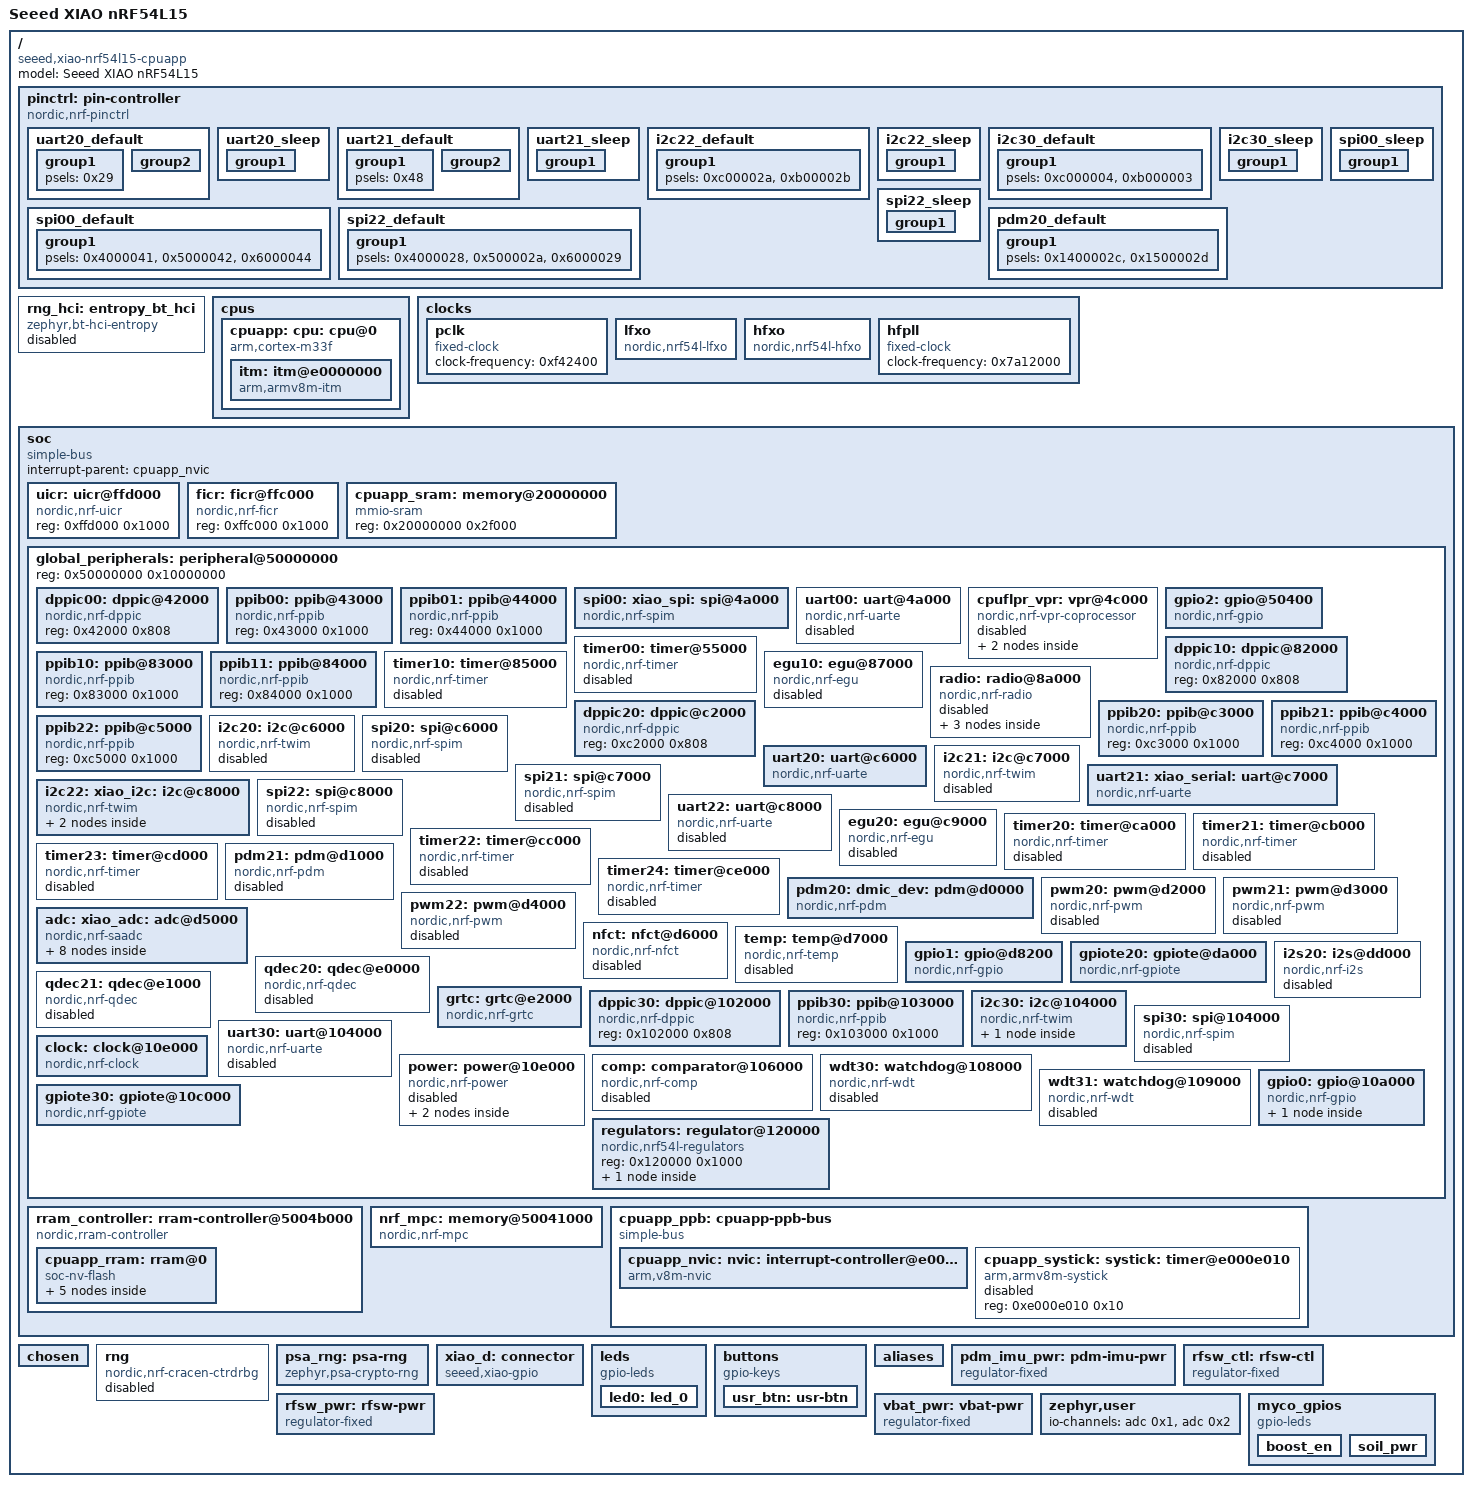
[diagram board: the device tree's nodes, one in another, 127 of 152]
/dts-v1/;

/* node '/' defined in zephyr/dts/vendor/nordic/nrf_common.dtsi:25 */
/ {
	#address-cells = < 0x1 >;                  /* in zephyr/dts/vendor/nordic/nrf54l_05_10_15.dtsi:19 */
	#size-cells = < 0x1 >;                     /* in zephyr/dts/vendor/nordic/nrf54l_05_10_15.dtsi:20 */
	model = "Seeed XIAO nRF54L15";             /* in zephyr/boards/seeed/xiao_nrf54l15/xiao_nrf54l15_nrf54l15_cpuapp.dts:11 */
	compatible = "seeed,xiao-nrf54l15-cpuapp"; /* in zephyr/boards/seeed/xiao_nrf54l15/xiao_nrf54l15_nrf54l15_cpuapp.dts:12 */

	/* node '/pin-controller' defined in zephyr/dts/vendor/nordic/nrf_common.dtsi:26 */
	pinctrl: pin-controller {
		compatible = "nordic,nrf-pinctrl"; /* in zephyr/dts/vendor/nordic/nrf_common.dtsi:31 */

		/* node '/pin-controller/uart20_default' defined in zephyr/boards/seeed/xiao_nrf54l15/xiao_nrf54l15-pinctrl.dtsi:6 */
		uart20_default: uart20_default {
			phandle = < 0x6 >; /* in zephyr/boards/seeed/xiao_nrf54l15/xiao_nrf54l15_common.dtsi:39 */

			/* node '/pin-controller/uart20_default/group1' defined in zephyr/boards/seeed/xiao_nrf54l15/xiao_nrf54l15-pinctrl.dtsi:7 */
			group1 {
				psels = < 0x29 >; /* in zephyr/boards/seeed/xiao_nrf54l15/xiao_nrf54l15-pinctrl.dtsi:8 */
			};

			/* node '/pin-controller/uart20_default/group2' defined in zephyr/boards/seeed/xiao_nrf54l15/xiao_nrf54l15-pinctrl.dtsi:11 */
			group2 {
				psels = < 0x1000028 >; /* in zephyr/boards/seeed/xiao_nrf54l15/xiao_nrf54l15-pinctrl.dtsi:12 */
				bias-pull-up;          /* in zephyr/boards/seeed/xiao_nrf54l15/xiao_nrf54l15-pinctrl.dtsi:13 */
			};
		};

		/* node '/pin-controller/uart20_sleep' defined in zephyr/boards/seeed/xiao_nrf54l15/xiao_nrf54l15-pinctrl.dtsi:17 */
		uart20_sleep: uart20_sleep {
			phandle = < 0x7 >; /* in zephyr/boards/seeed/xiao_nrf54l15/xiao_nrf54l15_common.dtsi:40 */

			/* node '/pin-controller/uart20_sleep/group1' defined in zephyr/boards/seeed/xiao_nrf54l15/xiao_nrf54l15-pinctrl.dtsi:18 */
			group1 {
				psels = < 0x29 >,
				        < 0x1000028 >; /* in zephyr/boards/seeed/xiao_nrf54l15/xiao_nrf54l15-pinctrl.dtsi:19 */
				low-power-enable;      /* in zephyr/boards/seeed/xiao_nrf54l15/xiao_nrf54l15-pinctrl.dtsi:21 */
			};
		};

		/* node '/pin-controller/uart21_default' defined in zephyr/boards/seeed/xiao_nrf54l15/xiao_nrf54l15-pinctrl.dtsi:25 */
		uart21_default: uart21_default {
			phandle = < 0x8 >; /* in zephyr/boards/seeed/xiao_nrf54l15/xiao_nrf54l15_common.dtsi:46 */

			/* node '/pin-controller/uart21_default/group1' defined in zephyr/boards/seeed/xiao_nrf54l15/xiao_nrf54l15-pinctrl.dtsi:26 */
			group1 {
				psels = < 0x48 >; /* in zephyr/boards/seeed/xiao_nrf54l15/xiao_nrf54l15-pinctrl.dtsi:27 */
			};

			/* node '/pin-controller/uart21_default/group2' defined in zephyr/boards/seeed/xiao_nrf54l15/xiao_nrf54l15-pinctrl.dtsi:30 */
			group2 {
				psels = < 0x1000047 >; /* in zephyr/boards/seeed/xiao_nrf54l15/xiao_nrf54l15-pinctrl.dtsi:31 */
				bias-pull-up;          /* in zephyr/boards/seeed/xiao_nrf54l15/xiao_nrf54l15-pinctrl.dtsi:32 */
			};
		};

		/* node '/pin-controller/uart21_sleep' defined in zephyr/boards/seeed/xiao_nrf54l15/xiao_nrf54l15-pinctrl.dtsi:36 */
		uart21_sleep: uart21_sleep {
			phandle = < 0x9 >; /* in zephyr/boards/seeed/xiao_nrf54l15/xiao_nrf54l15_common.dtsi:47 */

			/* node '/pin-controller/uart21_sleep/group1' defined in zephyr/boards/seeed/xiao_nrf54l15/xiao_nrf54l15-pinctrl.dtsi:37 */
			group1 {
				psels = < 0x48 >,
				        < 0x1000047 >; /* in zephyr/boards/seeed/xiao_nrf54l15/xiao_nrf54l15-pinctrl.dtsi:38 */
				low-power-enable;      /* in zephyr/boards/seeed/xiao_nrf54l15/xiao_nrf54l15-pinctrl.dtsi:40 */
			};
		};

		/* node '/pin-controller/i2c22_default' defined in zephyr/boards/seeed/xiao_nrf54l15/xiao_nrf54l15-pinctrl.dtsi:44 */
		i2c22_default: i2c22_default {
			phandle = < 0xa >; /* in zephyr/boards/seeed/xiao_nrf54l15/xiao_nrf54l15_common.dtsi:52 */

			/* node '/pin-controller/i2c22_default/group1' defined in zephyr/boards/seeed/xiao_nrf54l15/xiao_nrf54l15-pinctrl.dtsi:45 */
			group1 {
				psels = < 0xc00002a >,
				        < 0xb00002b >; /* in zephyr/boards/seeed/xiao_nrf54l15/xiao_nrf54l15-pinctrl.dtsi:46 */
			};
		};

		/* node '/pin-controller/i2c22_sleep' defined in zephyr/boards/seeed/xiao_nrf54l15/xiao_nrf54l15-pinctrl.dtsi:51 */
		i2c22_sleep: i2c22_sleep {
			phandle = < 0xb >; /* in zephyr/boards/seeed/xiao_nrf54l15/xiao_nrf54l15_common.dtsi:53 */

			/* node '/pin-controller/i2c22_sleep/group1' defined in zephyr/boards/seeed/xiao_nrf54l15/xiao_nrf54l15-pinctrl.dtsi:52 */
			group1 {
				psels = < 0xc00002a >,
				        < 0xb00002b >; /* in zephyr/boards/seeed/xiao_nrf54l15/xiao_nrf54l15-pinctrl.dtsi:53 */
				low-power-enable;      /* in zephyr/boards/seeed/xiao_nrf54l15/xiao_nrf54l15-pinctrl.dtsi:55 */
			};
		};

		/* node '/pin-controller/i2c30_default' defined in zephyr/boards/seeed/xiao_nrf54l15/xiao_nrf54l15-pinctrl.dtsi:59 */
		i2c30_default: i2c30_default {
			phandle = < 0x12 >; /* in zephyr/boards/seeed/xiao_nrf54l15/xiao_nrf54l15_common.dtsi:59 */

			/* node '/pin-controller/i2c30_default/group1' defined in zephyr/boards/seeed/xiao_nrf54l15/xiao_nrf54l15-pinctrl.dtsi:60 */
			group1 {
				psels = < 0xc000004 >,
				        < 0xb000003 >; /* in zephyr/boards/seeed/xiao_nrf54l15/xiao_nrf54l15-pinctrl.dtsi:61 */
			};
		};

		/* node '/pin-controller/i2c30_sleep' defined in zephyr/boards/seeed/xiao_nrf54l15/xiao_nrf54l15-pinctrl.dtsi:66 */
		i2c30_sleep: i2c30_sleep {
			phandle = < 0x13 >; /* in zephyr/boards/seeed/xiao_nrf54l15/xiao_nrf54l15_common.dtsi:60 */

			/* node '/pin-controller/i2c30_sleep/group1' defined in zephyr/boards/seeed/xiao_nrf54l15/xiao_nrf54l15-pinctrl.dtsi:67 */
			group1 {
				psels = < 0xc000004 >,
				        < 0xb000003 >; /* in zephyr/boards/seeed/xiao_nrf54l15/xiao_nrf54l15-pinctrl.dtsi:68 */
				low-power-enable;      /* in zephyr/boards/seeed/xiao_nrf54l15/xiao_nrf54l15-pinctrl.dtsi:70 */
			};
		};

		/* node '/pin-controller/spi00_default' defined in zephyr/boards/seeed/xiao_nrf54l15/xiao_nrf54l15-pinctrl.dtsi:74 */
		spi00_default: spi00_default {
			phandle = < 0x3 >; /* in zephyr/boards/seeed/xiao_nrf54l15/xiao_nrf54l15_common.dtsi:66 */

			/* node '/pin-controller/spi00_default/group1' defined in zephyr/boards/seeed/xiao_nrf54l15/xiao_nrf54l15-pinctrl.dtsi:75 */
			group1 {
				psels = < 0x4000041 >,
				        < 0x5000042 >,
				        < 0x6000044 >; /* in zephyr/boards/seeed/xiao_nrf54l15/xiao_nrf54l15-pinctrl.dtsi:76 */
			};
		};

		/* node '/pin-controller/spi00_sleep' defined in zephyr/boards/seeed/xiao_nrf54l15/xiao_nrf54l15-pinctrl.dtsi:82 */
		spi00_sleep: spi00_sleep {
			phandle = < 0x4 >; /* in zephyr/boards/seeed/xiao_nrf54l15/xiao_nrf54l15_common.dtsi:67 */

			/* node '/pin-controller/spi00_sleep/group1' defined in zephyr/boards/seeed/xiao_nrf54l15/xiao_nrf54l15-pinctrl.dtsi:83 */
			group1 {
				psels = < 0x4000041 >,
				        < 0x5000042 >,
				        < 0x6000044 >; /* in zephyr/boards/seeed/xiao_nrf54l15/xiao_nrf54l15-pinctrl.dtsi:84 */
				low-power-enable;      /* in zephyr/boards/seeed/xiao_nrf54l15/xiao_nrf54l15-pinctrl.dtsi:87 */
			};
		};

		/* node '/pin-controller/spi22_default' defined in zephyr/boards/seeed/xiao_nrf54l15/xiao_nrf54l15-pinctrl.dtsi:91 */
		spi22_default: spi22_default {
			phandle = < 0xc >; /* in zephyr/boards/seeed/xiao_nrf54l15/xiao_nrf54l15_common.dtsi:72 */

			/* node '/pin-controller/spi22_default/group1' defined in zephyr/boards/seeed/xiao_nrf54l15/xiao_nrf54l15-pinctrl.dtsi:92 */
			group1 {
				psels = < 0x4000028 >,
				        < 0x500002a >,
				        < 0x6000029 >; /* in zephyr/boards/seeed/xiao_nrf54l15/xiao_nrf54l15-pinctrl.dtsi:93 */
			};
		};

		/* node '/pin-controller/spi22_sleep' defined in zephyr/boards/seeed/xiao_nrf54l15/xiao_nrf54l15-pinctrl.dtsi:99 */
		spi22_sleep: spi22_sleep {
			phandle = < 0xd >; /* in zephyr/boards/seeed/xiao_nrf54l15/xiao_nrf54l15_common.dtsi:73 */

			/* node '/pin-controller/spi22_sleep/group1' defined in zephyr/boards/seeed/xiao_nrf54l15/xiao_nrf54l15-pinctrl.dtsi:100 */
			group1 {
				psels = < 0x4000028 >,
				        < 0x500002a >,
				        < 0x6000029 >; /* in zephyr/boards/seeed/xiao_nrf54l15/xiao_nrf54l15-pinctrl.dtsi:101 */
				low-power-enable;      /* in zephyr/boards/seeed/xiao_nrf54l15/xiao_nrf54l15-pinctrl.dtsi:104 */
			};
		};

		/* node '/pin-controller/pdm20_default' defined in zephyr/boards/seeed/xiao_nrf54l15/xiao_nrf54l15-pinctrl.dtsi:108 */
		pdm20_default: pdm20_default {
			phandle = < 0xe >; /* in zephyr/boards/seeed/xiao_nrf54l15/xiao_nrf54l15_common.dtsi:78 */

			/* node '/pin-controller/pdm20_default/group1' defined in zephyr/boards/seeed/xiao_nrf54l15/xiao_nrf54l15-pinctrl.dtsi:109 */
			group1 {
				psels = < 0x1400002c >,
				        < 0x1500002d >; /* in zephyr/boards/seeed/xiao_nrf54l15/xiao_nrf54l15-pinctrl.dtsi:110 */
			};
		};
	};

	/* node '/entropy_bt_hci' defined in zephyr/dts/vendor/nordic/nrf_common.dtsi:34 */
	rng_hci: entropy_bt_hci {
		compatible = "zephyr,bt-hci-entropy"; /* in zephyr/dts/vendor/nordic/nrf_common.dtsi:35 */
		status = "disabled";                  /* in zephyr/dts/vendor/nordic/nrf_common.dtsi:36 */
	};

	/* node '/cpus' defined in zephyr/dts/vendor/nordic/nrf54l_05_10_15.dtsi:22 */
	cpus {
		#address-cells = < 0x1 >; /* in zephyr/dts/vendor/nordic/nrf54l_05_10_15.dtsi:23 */
		#size-cells = < 0x0 >;    /* in zephyr/dts/vendor/nordic/nrf54l_05_10_15.dtsi:24 */

		/* node '/cpus/cpu@0' defined in zephyr/dts/vendor/nordic/nrf54l_05_10_15.dtsi:26 */
		cpuapp: cpu: cpu@0 {
			compatible = "arm,cortex-m33f"; /* in zephyr/dts/vendor/nordic/nrf54l_05_10_15.dtsi:27 */
			reg = < 0x0 >;                  /* in zephyr/dts/vendor/nordic/nrf54l_05_10_15.dtsi:28 */
			device_type = "cpu";            /* in zephyr/dts/vendor/nordic/nrf54l_05_10_15.dtsi:29 */
			clocks = < &hfpll >;            /* in zephyr/dts/vendor/nordic/nrf54l_05_10_15.dtsi:30 */
			#address-cells = < 0x1 >;       /* in zephyr/dts/vendor/nordic/nrf54l_05_10_15.dtsi:31 */
			#size-cells = < 0x1 >;          /* in zephyr/dts/vendor/nordic/nrf54l_05_10_15.dtsi:32 */

			/* node '/cpus/cpu@0/itm@e0000000' defined in zephyr/dts/vendor/nordic/nrf54l_05_10_15.dtsi:34 */
			itm: itm@e0000000 {
				compatible = "arm,armv8m-itm";     /* in zephyr/dts/vendor/nordic/nrf54l_05_10_15.dtsi:35 */
				reg = < 0xe0000000 0x1000 >;       /* in zephyr/dts/vendor/nordic/nrf54l_05_10_15.dtsi:36 */
				swo-ref-frequency = < 0x7a12000 >; /* in zephyr/dts/vendor/nordic/nrf54l_05_10_15.dtsi:37 */
			};
		};
	};

	/* node '/clocks' defined in zephyr/dts/vendor/nordic/nrf54l_05_10_15.dtsi:51 */
	clocks {

		/* node '/clocks/pclk' defined in zephyr/dts/vendor/nordic/nrf54l_05_10_15.dtsi:52 */
		pclk: pclk {
			compatible = "fixed-clock";     /* in zephyr/dts/vendor/nordic/nrf54l_05_10_15.dtsi:53 */
			#clock-cells = < 0x0 >;         /* in zephyr/dts/vendor/nordic/nrf54l_05_10_15.dtsi:54 */
			clock-frequency = < 0xf42400 >; /* in zephyr/dts/vendor/nordic/nrf54l_05_10_15.dtsi:55 */
			phandle = < 0x11 >;             /* in zephyr/dts/vendor/nordic/nrf54l_05_10_15.dtsi:574 */
		};

		/* node '/clocks/lfxo' defined in zephyr/dts/vendor/nordic/nrf54l_05_10_15.dtsi:58 */
		lfxo: lfxo {
			compatible = "nordic,nrf54l-lfxo";        /* in zephyr/dts/vendor/nordic/nrf54l_05_10_15.dtsi:59 */
			#clock-cells = < 0x0 >;                   /* in zephyr/dts/vendor/nordic/nrf54l_05_10_15.dtsi:60 */
			clock-frequency = < 0x8000 >;             /* in zephyr/dts/vendor/nordic/nrf54l_05_10_15.dtsi:61 */
			load-capacitors = "internal";             /* in zephyr/boards/seeed/xiao_nrf54l15/xiao_nrf54l15_nrf54l15_cpuapp.dts:142 */
			load-capacitance-femtofarad = < 0x3e80 >; /* in zephyr/boards/seeed/xiao_nrf54l15/xiao_nrf54l15_nrf54l15_cpuapp.dts:143 */
			status = "okay";                          /* in zephyr/boards/seeed/xiao_nrf54l15/xiao_nrf54l15_nrf54l15_cpuapp.dts:144 */
			phandle = < 0x10 >;                       /* in zephyr/dts/vendor/nordic/nrf54l_05_10_15.dtsi:574 */
		};

		/* node '/clocks/hfxo' defined in zephyr/dts/vendor/nordic/nrf54l_05_10_15.dtsi:64 */
		hfxo: hfxo {
			compatible = "nordic,nrf54l-hfxo"; /* in zephyr/dts/vendor/nordic/nrf54l_05_10_15.dtsi:65 */
			#clock-cells = < 0x0 >;            /* in zephyr/dts/vendor/nordic/nrf54l_05_10_15.dtsi:66 */
			clock-frequency = < 0x1e84800 >;   /* in zephyr/dts/vendor/nordic/nrf54l_05_10_15.dtsi:67 */
			startup-time-us = < 0x672 >;       /* in zephyr/dts/vendor/nordic/nrf54l_05_10_15.dtsi:68 */
			phandle = < 0x5 >;                 /* in zephyr/dts/vendor/nordic/nrf54l_05_10_15.dtsi:229 */
		};

		/* node '/clocks/hfpll' defined in zephyr/dts/vendor/nordic/nrf54l_05_10_15.dtsi:71 */
		hfpll: hfpll {
			compatible = "fixed-clock";      /* in zephyr/dts/vendor/nordic/nrf54l_05_10_15.dtsi:72 */
			#clock-cells = < 0x0 >;          /* in zephyr/dts/vendor/nordic/nrf54l_05_10_15.dtsi:73 */
			clock-frequency = < 0x7a12000 >; /* in zephyr/dts/vendor/nordic/nrf54l_05_10_15.dtsi:74 */
			phandle = < 0x1 >;               /* in zephyr/dts/vendor/nordic/nrf54l_05_10_15.dtsi:30 */
		};
	};

	/* node '/soc' defined in zephyr/dts/vendor/nordic/nrf54l_05_10_15.dtsi:78 */
	soc {
		#address-cells = < 0x1 >;            /* in zephyr/dts/vendor/nordic/nrf54l_05_10_15.dtsi:79 */
		#size-cells = < 0x1 >;               /* in zephyr/dts/vendor/nordic/nrf54l_05_10_15.dtsi:80 */
		compatible = "simple-bus";           /* in zephyr/dts/arm/nordic/nrf54l_05_10_15_cpuapp.dtsi:25 */
		interrupt-parent = < &cpuapp_nvic >; /* in zephyr/dts/arm/nordic/nrf54l_05_10_15_cpuapp.dtsi:26 */
		ranges;                              /* in zephyr/dts/arm/nordic/nrf54l_05_10_15_cpuapp.dtsi:27 */

		/* node '/soc/uicr@ffd000' defined in zephyr/dts/vendor/nordic/nrf54l_05_10_15.dtsi:85 */
		uicr: uicr@ffd000 {
			compatible = "nordic,nrf-uicr"; /* in zephyr/dts/vendor/nordic/nrf54l_05_10_15.dtsi:86 */
			reg = < 0xffd000 0x1000 >;      /* in zephyr/dts/vendor/nordic/nrf54l_05_10_15.dtsi:87 */
		};

		/* node '/soc/ficr@ffc000' defined in zephyr/dts/vendor/nordic/nrf54l_05_10_15.dtsi:90 */
		ficr: ficr@ffc000 {
			compatible = "nordic,nrf-ficr"; /* in zephyr/dts/vendor/nordic/nrf54l_05_10_15.dtsi:91 */
			reg = < 0xffc000 0x1000 >;      /* in zephyr/dts/vendor/nordic/nrf54l_05_10_15.dtsi:92 */
			#nordic,ficr-cells = < 0x1 >;   /* in zephyr/dts/vendor/nordic/nrf54l_05_10_15.dtsi:93 */
		};

		/* node '/soc/memory@20000000' defined in zephyr/dts/vendor/nordic/nrf54l_05_10_15.dtsi:96 */
		cpuapp_sram: memory@20000000 {
			compatible = "mmio-sram";            /* in zephyr/dts/vendor/nordic/nrf54l_05_10_15.dtsi:97 */
			#address-cells = < 0x1 >;            /* in zephyr/dts/vendor/nordic/nrf54l_05_10_15.dtsi:98 */
			#size-cells = < 0x1 >;               /* in zephyr/dts/vendor/nordic/nrf54l_05_10_15.dtsi:99 */
			reg = < 0x20000000 0x2f000 >;        /* in zephyr/dts/vendor/nordic/nrf54l15.dtsi:10 */
			ranges = < 0x0 0x20000000 0x2f000 >; /* in zephyr/dts/vendor/nordic/nrf54l15.dtsi:11 */
			status = "okay";                     /* in zephyr/boards/seeed/xiao_nrf54l15/xiao_nrf54l15_nrf54l15_cpuapp.dts:55 */
		};

		/* node '/soc/peripheral@50000000' defined in zephyr/dts/vendor/nordic/nrf54l_05_10_15.dtsi:110 */
		global_peripherals: peripheral@50000000 {
			reg = < 0x50000000 0x10000000 >;        /* in zephyr/dts/vendor/nordic/nrf54l_05_10_15.dtsi:111 */
			#address-cells = < 0x1 >;               /* in zephyr/dts/vendor/nordic/nrf54l_05_10_15.dtsi:112 */
			#size-cells = < 0x1 >;                  /* in zephyr/dts/vendor/nordic/nrf54l_05_10_15.dtsi:113 */
			ranges = < 0x0 0x50000000 0x10000000 >; /* in zephyr/dts/vendor/nordic/nrf54l_05_10_15.dtsi:114 */

			/* node '/soc/peripheral@50000000/dppic@42000' defined in zephyr/dts/vendor/nordic/nrf54l_05_10_15.dtsi:117 */
			dppic00: dppic@42000 {
				compatible = "nordic,nrf-dppic"; /* in zephyr/dts/vendor/nordic/nrf54l_05_10_15.dtsi:118 */
				reg = < 0x42000 0x808 >;         /* in zephyr/dts/vendor/nordic/nrf54l_05_10_15.dtsi:119 */
				status = "okay";                 /* in zephyr/dts/arm/nordic/nrf54l_05_10_15_cpuapp.dtsi:97 */
			};

			/* node '/soc/peripheral@50000000/ppib@43000' defined in zephyr/dts/vendor/nordic/nrf54l_05_10_15.dtsi:123 */
			ppib00: ppib@43000 {
				compatible = "nordic,nrf-ppib"; /* in zephyr/dts/vendor/nordic/nrf54l_05_10_15.dtsi:124 */
				reg = < 0x43000 0x1000 >;       /* in zephyr/dts/vendor/nordic/nrf54l_05_10_15.dtsi:125 */
				status = "okay";                /* in zephyr/dts/arm/nordic/nrf54l_05_10_15_cpuapp.dtsi:113 */
			};

			/* node '/soc/peripheral@50000000/ppib@44000' defined in zephyr/dts/vendor/nordic/nrf54l_05_10_15.dtsi:129 */
			ppib01: ppib@44000 {
				compatible = "nordic,nrf-ppib"; /* in zephyr/dts/vendor/nordic/nrf54l_05_10_15.dtsi:130 */
				reg = < 0x44000 0x1000 >;       /* in zephyr/dts/vendor/nordic/nrf54l_05_10_15.dtsi:131 */
				status = "okay";                /* in zephyr/dts/arm/nordic/nrf54l_05_10_15_cpuapp.dtsi:117 */
			};

			/* node '/soc/peripheral@50000000/spi@4a000' defined in zephyr/dts/vendor/nordic/nrf54l_05_10_15.dtsi:135 */
			spi00: xiao_spi: spi@4a000 {
				compatible = "nordic,nrf-spim"; /* in zephyr/dts/vendor/nordic/nrf54l_05_10_15.dtsi:142 */
				#address-cells = < 0x1 >;       /* in zephyr/dts/vendor/nordic/nrf54l_05_10_15.dtsi:143 */
				#size-cells = < 0x0 >;          /* in zephyr/dts/vendor/nordic/nrf54l_05_10_15.dtsi:144 */
				reg = < 0x4a000 0x1000 >;       /* in zephyr/dts/vendor/nordic/nrf54l_05_10_15.dtsi:145 */
				interrupts = < 0x4a 0x1 >;      /* in zephyr/dts/vendor/nordic/nrf54l_05_10_15.dtsi:146 */
				max-frequency = < 0x1e84800 >;  /* in zephyr/dts/vendor/nordic/nrf54l_05_10_15.dtsi:147 */
				easydma-maxcnt-bits = < 0x10 >; /* in zephyr/dts/vendor/nordic/nrf54l_05_10_15.dtsi:148 */
				rx-delay-supported;             /* in zephyr/dts/vendor/nordic/nrf54l_05_10_15.dtsi:149 */
				rx-delay = < 0x1 >;             /* in zephyr/dts/vendor/nordic/nrf54l_05_10_15.dtsi:150 */
				pinctrl-0 = < &spi00_default >; /* in zephyr/boards/seeed/xiao_nrf54l15/xiao_nrf54l15_common.dtsi:66 */
				pinctrl-1 = < &spi00_sleep >;   /* in zephyr/boards/seeed/xiao_nrf54l15/xiao_nrf54l15_common.dtsi:67 */
				pinctrl-names = "default",
				                "sleep";        /* in zephyr/boards/seeed/xiao_nrf54l15/xiao_nrf54l15_common.dtsi:68 */
				status = "okay";                /* in zephyr/boards/seeed/xiao_nrf54l15/xiao_nrf54l15_nrf54l15_cpuapp.dts:95 */
			};

			/* node '/soc/peripheral@50000000/uart@4a000' defined in zephyr/dts/vendor/nordic/nrf54l_05_10_15.dtsi:154 */
			uart00: uart@4a000 {
				compatible = "nordic,nrf-uarte"; /* in zephyr/dts/vendor/nordic/nrf54l_05_10_15.dtsi:155 */
				reg = < 0x4a000 0x1000 >;        /* in zephyr/dts/vendor/nordic/nrf54l_05_10_15.dtsi:156 */
				interrupts = < 0x4a 0x1 >;       /* in zephyr/dts/vendor/nordic/nrf54l_05_10_15.dtsi:157 */
				clocks = < &hfpll >;             /* in zephyr/dts/vendor/nordic/nrf54l_05_10_15.dtsi:158 */
				status = "disabled";             /* in zephyr/dts/vendor/nordic/nrf54l_05_10_15.dtsi:159 */
				endtx-stoptx-supported;          /* in zephyr/dts/vendor/nordic/nrf54l_05_10_15.dtsi:160 */
				frame-timeout-supported;         /* in zephyr/dts/vendor/nordic/nrf54l_05_10_15.dtsi:161 */
			};

			/* node '/soc/peripheral@50000000/vpr@4c000' defined in zephyr/dts/vendor/nordic/nrf54l_05_10_15.dtsi:164 */
			cpuflpr_vpr: vpr@4c000 {
				compatible = "nordic,nrf-vpr-coprocessor"; /* in zephyr/dts/vendor/nordic/nrf54l_05_10_15.dtsi:165 */
				reg = < 0x4c000 0x1000 >;                  /* in zephyr/dts/vendor/nordic/nrf54l_05_10_15.dtsi:166 */
				ranges = < 0x0 0x4c000 0x1000 >;           /* in zephyr/dts/vendor/nordic/nrf54l_05_10_15.dtsi:167 */
				#address-cells = < 0x1 >;                  /* in zephyr/dts/vendor/nordic/nrf54l_05_10_15.dtsi:168 */
				#size-cells = < 0x1 >;                     /* in zephyr/dts/vendor/nordic/nrf54l_05_10_15.dtsi:169 */
				status = "disabled";                       /* in zephyr/dts/vendor/nordic/nrf54l_05_10_15.dtsi:170 */
				enable-secure;                             /* in zephyr/dts/vendor/nordic/nrf54l_05_10_15.dtsi:171 */

				/* node '/soc/peripheral@50000000/vpr@4c000/mailbox@1' defined in zephyr/dts/arm/nordic/nrf54l_05_10_15_cpuapp.dtsi:46 */
				cpuapp_vevif_rx: mailbox@1 {
					compatible = "nordic,nrf-vevif-event-rx"; /* in zephyr/dts/arm/nordic/nrf54l_05_10_15_cpuapp.dtsi:47 */
					reg = < 0x1 0x1000 >;                     /* in zephyr/dts/arm/nordic/nrf54l_05_10_15_cpuapp.dtsi:48 */
					status = "disabled";                      /* in zephyr/dts/arm/nordic/nrf54l_05_10_15_cpuapp.dtsi:49 */
					interrupts = < 0x4c 0x1 >;                /* in zephyr/dts/arm/nordic/nrf54l_05_10_15_cpuapp.dtsi:50 */
					#mbox-cells = < 0x1 >;                    /* in zephyr/dts/arm/nordic/nrf54l_05_10_15_cpuapp.dtsi:51 */
					nordic,events = < 0x1 >;                  /* in zephyr/dts/arm/nordic/nrf54l_05_10_15_cpuapp.dtsi:52 */
					nordic,events-mask = < 0x100000 >;        /* in zephyr/dts/arm/nordic/nrf54l_05_10_15_cpuapp.dtsi:53 */
				};

				/* node '/soc/peripheral@50000000/vpr@4c000/mailbox@0' defined in zephyr/dts/arm/nordic/nrf54l_05_10_15_cpuapp.dtsi:56 */
				cpuapp_vevif_tx: mailbox@0 {
					compatible = "nordic,nrf-vevif-task-tx"; /* in zephyr/dts/arm/nordic/nrf54l_05_10_15_cpuapp.dtsi:57 */
					reg = < 0x0 0x1000 >;                    /* in zephyr/dts/arm/nordic/nrf54l_05_10_15_cpuapp.dtsi:58 */
					#mbox-cells = < 0x1 >;                   /* in zephyr/dts/arm/nordic/nrf54l_05_10_15_cpuapp.dtsi:59 */
					nordic,tasks = < 0x7 >;                  /* in zephyr/dts/arm/nordic/nrf54l_05_10_15_cpuapp.dtsi:60 */
					nordic,tasks-mask = < 0x7f0000 >;        /* in zephyr/dts/arm/nordic/nrf54l_05_10_15_cpuapp.dtsi:61 */
					status = "disabled";                     /* in zephyr/dts/arm/nordic/nrf54l_05_10_15_cpuapp.dtsi:62 */
				};
			};

			/* node '/soc/peripheral@50000000/gpio@50400' defined in zephyr/dts/vendor/nordic/nrf54l_05_10_15.dtsi:183 */
			gpio2: gpio@50400 {
				compatible = "nordic,nrf-gpio"; /* in zephyr/dts/vendor/nordic/nrf54l_05_10_15.dtsi:184 */
				gpio-controller;                /* in zephyr/dts/vendor/nordic/nrf54l_05_10_15.dtsi:185 */
				reg = < 0x50400 0x300 >;        /* in zephyr/dts/vendor/nordic/nrf54l_05_10_15.dtsi:186 */
				#gpio-cells = < 0x2 >;          /* in zephyr/dts/vendor/nordic/nrf54l_05_10_15.dtsi:187 */
				ngpios = < 0xb >;               /* in zephyr/dts/vendor/nordic/nrf54l_05_10_15.dtsi:188 */
				port = < 0x2 >;                 /* in zephyr/dts/vendor/nordic/nrf54l_05_10_15.dtsi:190 */
				status = "okay";                /* in zephyr/boards/seeed/xiao_nrf54l15/xiao_nrf54l15_nrf54l15_cpuapp.dts:121 */
				phandle = < 0x17 >;             /* in zephyr/boards/seeed/xiao_nrf54l15/seeed_xiao_connector.dtsi:11 */
			};

			/* node '/soc/peripheral@50000000/timer@55000' defined in zephyr/dts/vendor/nordic/nrf54l_05_10_15.dtsi:193 */
			timer00: timer@55000 {
				compatible = "nordic,nrf-timer"; /* in zephyr/dts/vendor/nordic/nrf54l_05_10_15.dtsi:194 */
				status = "disabled";             /* in zephyr/dts/vendor/nordic/nrf54l_05_10_15.dtsi:195 */
				reg = < 0x55000 0x1000 >;        /* in zephyr/dts/vendor/nordic/nrf54l_05_10_15.dtsi:196 */
				cc-num = < 0x6 >;                /* in zephyr/dts/vendor/nordic/nrf54l_05_10_15.dtsi:197 */
				max-bit-width = < 0x20 >;        /* in zephyr/dts/vendor/nordic/nrf54l_05_10_15.dtsi:198 */
				interrupts = < 0x55 0x1 >;       /* in zephyr/dts/vendor/nordic/nrf54l_05_10_15.dtsi:199 */
				clocks = < &hfpll >;             /* in zephyr/dts/vendor/nordic/nrf54l_05_10_15.dtsi:200 */
				prescaler = < 0x0 >;             /* in zephyr/dts/vendor/nordic/nrf54l_05_10_15.dtsi:201 */
			};

			/* node '/soc/peripheral@50000000/dppic@82000' defined in zephyr/dts/vendor/nordic/nrf54l_05_10_15.dtsi:204 */
			dppic10: dppic@82000 {
				compatible = "nordic,nrf-dppic"; /* in zephyr/dts/vendor/nordic/nrf54l_05_10_15.dtsi:205 */
				reg = < 0x82000 0x808 >;         /* in zephyr/dts/vendor/nordic/nrf54l_05_10_15.dtsi:206 */
				status = "okay";                 /* in zephyr/dts/arm/nordic/nrf54l_05_10_15_cpuapp.dtsi:101 */
			};

			/* node '/soc/peripheral@50000000/ppib@83000' defined in zephyr/dts/vendor/nordic/nrf54l_05_10_15.dtsi:210 */
			ppib10: ppib@83000 {
				compatible = "nordic,nrf-ppib"; /* in zephyr/dts/vendor/nordic/nrf54l_05_10_15.dtsi:211 */
				reg = < 0x83000 0x1000 >;       /* in zephyr/dts/vendor/nordic/nrf54l_05_10_15.dtsi:212 */
				status = "okay";                /* in zephyr/dts/arm/nordic/nrf54l_05_10_15_cpuapp.dtsi:121 */
			};

			/* node '/soc/peripheral@50000000/ppib@84000' defined in zephyr/dts/vendor/nordic/nrf54l_05_10_15.dtsi:216 */
			ppib11: ppib@84000 {
				compatible = "nordic,nrf-ppib"; /* in zephyr/dts/vendor/nordic/nrf54l_05_10_15.dtsi:217 */
				reg = < 0x84000 0x1000 >;       /* in zephyr/dts/vendor/nordic/nrf54l_05_10_15.dtsi:218 */
				status = "okay";                /* in zephyr/dts/arm/nordic/nrf54l_05_10_15_cpuapp.dtsi:125 */
			};

			/* node '/soc/peripheral@50000000/timer@85000' defined in zephyr/dts/vendor/nordic/nrf54l_05_10_15.dtsi:222 */
			timer10: timer@85000 {
				compatible = "nordic,nrf-timer"; /* in zephyr/dts/vendor/nordic/nrf54l_05_10_15.dtsi:223 */
				status = "disabled";             /* in zephyr/dts/vendor/nordic/nrf54l_05_10_15.dtsi:224 */
				reg = < 0x85000 0x1000 >;        /* in zephyr/dts/vendor/nordic/nrf54l_05_10_15.dtsi:225 */
				cc-num = < 0x8 >;                /* in zephyr/dts/vendor/nordic/nrf54l_05_10_15.dtsi:226 */
				max-bit-width = < 0x20 >;        /* in zephyr/dts/vendor/nordic/nrf54l_05_10_15.dtsi:227 */
				interrupts = < 0x85 0x1 >;       /* in zephyr/dts/vendor/nordic/nrf54l_05_10_15.dtsi:228 */
				clocks = < &hfxo >;              /* in zephyr/dts/vendor/nordic/nrf54l_05_10_15.dtsi:229 */
				prescaler = < 0x0 >;             /* in zephyr/dts/vendor/nordic/nrf54l_05_10_15.dtsi:230 */
			};

			/* node '/soc/peripheral@50000000/egu@87000' defined in zephyr/dts/vendor/nordic/nrf54l_05_10_15.dtsi:233 */
			egu10: egu@87000 {
				compatible = "nordic,nrf-egu"; /* in zephyr/dts/vendor/nordic/nrf54l_05_10_15.dtsi:234 */
				reg = < 0x87000 0x1000 >;      /* in zephyr/dts/vendor/nordic/nrf54l_05_10_15.dtsi:235 */
				interrupts = < 0x87 0x1 >;     /* in zephyr/dts/vendor/nordic/nrf54l_05_10_15.dtsi:236 */
				status = "disabled";           /* in zephyr/dts/vendor/nordic/nrf54l_05_10_15.dtsi:237 */
			};

			/* node '/soc/peripheral@50000000/radio@8a000' defined in zephyr/dts/vendor/nordic/nrf54l_05_10_15.dtsi:240 */
			radio: radio@8a000 {
				compatible = "nordic,nrf-radio"; /* in zephyr/dts/vendor/nordic/nrf54l_05_10_15.dtsi:241 */
				reg = < 0x8a000 0x1000 >;        /* in zephyr/dts/vendor/nordic/nrf54l_05_10_15.dtsi:242 */
				interrupts = < 0x8a 0x1 >;       /* in zephyr/dts/vendor/nordic/nrf54l_05_10_15.dtsi:243 */
				status = "disabled";             /* in zephyr/dts/vendor/nordic/nrf54l_05_10_15.dtsi:244 */
				dfe-supported;                   /* in zephyr/dts/vendor/nordic/nrf54l_05_10_15.dtsi:245 */
				ieee802154-supported;            /* in zephyr/dts/vendor/nordic/nrf54l_05_10_15.dtsi:246 */
				ble-2mbps-supported;             /* in zephyr/dts/vendor/nordic/nrf54l_05_10_15.dtsi:247 */
				ble-coded-phy-supported;         /* in zephyr/dts/vendor/nordic/nrf54l_05_10_15.dtsi:248 */
				cs-supported;                    /* in zephyr/dts/vendor/nordic/nrf54l_05_10_15.dtsi:249 */

				/* node '/soc/peripheral@50000000/radio@8a000/ieee802154' defined in zephyr/dts/vendor/nordic/nrf54l_05_10_15.dtsi:251 */
				ieee802154: ieee802154 {
					compatible = "nordic,nrf-ieee802154"; /* in zephyr/dts/vendor/nordic/nrf54l_05_10_15.dtsi:252 */
					status = "disabled";                  /* in zephyr/dts/vendor/nordic/nrf54l_05_10_15.dtsi:253 */
				};

				/* node '/soc/peripheral@50000000/radio@8a000/bt_hci_sdc' defined in zephyr/dts/vendor/nordic/nrf54l_05_10_15.dtsi:256 */
				bt_hci_sdc: bt_hci_sdc {
					compatible = "nordic,bt-hci-sdc"; /* in zephyr/dts/vendor/nordic/nrf54l_05_10_15.dtsi:257 */
					status = "okay";                  /* in zephyr/dts/arm/nordic/nrf54l_05_10_15_cpuapp.dtsi:42 */
				};

				/* node '/soc/peripheral@50000000/radio@8a000/bt_hci_controller' defined in zephyr/dts/vendor/nordic/nrf54l_05_10_15.dtsi:261 */
				bt_hci_controller: bt_hci_controller {
					compatible = "zephyr,bt-hci-ll-sw-split"; /* in zephyr/dts/vendor/nordic/nrf54l_05_10_15.dtsi:262 */
					status = "disabled";                      /* in zephyr/dts/vendor/nordic/nrf54l_05_10_15.dtsi:263 */
				};
			};

			/* node '/soc/peripheral@50000000/dppic@c2000' defined in zephyr/dts/vendor/nordic/nrf54l_05_10_15.dtsi:267 */
			dppic20: dppic@c2000 {
				compatible = "nordic,nrf-dppic"; /* in zephyr/dts/vendor/nordic/nrf54l_05_10_15.dtsi:268 */
				reg = < 0xc2000 0x808 >;         /* in zephyr/dts/vendor/nordic/nrf54l_05_10_15.dtsi:269 */
				status = "okay";                 /* in zephyr/dts/arm/nordic/nrf54l_05_10_15_cpuapp.dtsi:105 */
			};

			/* node '/soc/peripheral@50000000/ppib@c3000' defined in zephyr/dts/vendor/nordic/nrf54l_05_10_15.dtsi:273 */
			ppib20: ppib@c3000 {
				compatible = "nordic,nrf-ppib"; /* in zephyr/dts/vendor/nordic/nrf54l_05_10_15.dtsi:274 */
				reg = < 0xc3000 0x1000 >;       /* in zephyr/dts/vendor/nordic/nrf54l_05_10_15.dtsi:275 */
				status = "okay";                /* in zephyr/dts/arm/nordic/nrf54l_05_10_15_cpuapp.dtsi:129 */
			};

			/* node '/soc/peripheral@50000000/ppib@c4000' defined in zephyr/dts/vendor/nordic/nrf54l_05_10_15.dtsi:279 */
			ppib21: ppib@c4000 {
				compatible = "nordic,nrf-ppib"; /* in zephyr/dts/vendor/nordic/nrf54l_05_10_15.dtsi:280 */
				reg = < 0xc4000 0x1000 >;       /* in zephyr/dts/vendor/nordic/nrf54l_05_10_15.dtsi:281 */
				status = "okay";                /* in zephyr/dts/arm/nordic/nrf54l_05_10_15_cpuapp.dtsi:133 */
			};

			/* node '/soc/peripheral@50000000/ppib@c5000' defined in zephyr/dts/vendor/nordic/nrf54l_05_10_15.dtsi:285 */
			ppib22: ppib@c5000 {
				compatible = "nordic,nrf-ppib"; /* in zephyr/dts/vendor/nordic/nrf54l_05_10_15.dtsi:286 */
				reg = < 0xc5000 0x1000 >;       /* in zephyr/dts/vendor/nordic/nrf54l_05_10_15.dtsi:287 */
				status = "okay";                /* in zephyr/dts/arm/nordic/nrf54l_05_10_15_cpuapp.dtsi:137 */
			};

			/* node '/soc/peripheral@50000000/i2c@c6000' defined in zephyr/dts/vendor/nordic/nrf54l_05_10_15.dtsi:291 */
			i2c20: i2c@c6000 {
				compatible = "nordic,nrf-twim"; /* in zephyr/dts/vendor/nordic/nrf54l_05_10_15.dtsi:292 */
				#address-cells = < 0x1 >;       /* in zephyr/dts/vendor/nordic/nrf54l_05_10_15.dtsi:293 */
				#size-cells = < 0x0 >;          /* in zephyr/dts/vendor/nordic/nrf54l_05_10_15.dtsi:294 */
				reg = < 0xc6000 0x1000 >;       /* in zephyr/dts/vendor/nordic/nrf54l_05_10_15.dtsi:295 */
				interrupts = < 0xc6 0x1 >;      /* in zephyr/dts/vendor/nordic/nrf54l_05_10_15.dtsi:296 */
				easydma-maxcnt-bits = < 0x10 >; /* in zephyr/dts/vendor/nordic/nrf54l_05_10_15.dtsi:297 */
				status = "disabled";            /* in zephyr/dts/vendor/nordic/nrf54l_05_10_15.dtsi:298 */
				zephyr,pm-device-runtime-auto;  /* in zephyr/dts/vendor/nordic/nrf54l_05_10_15.dtsi:299 */
			};

			/* node '/soc/peripheral@50000000/spi@c6000' defined in zephyr/dts/vendor/nordic/nrf54l_05_10_15.dtsi:302 */
			spi20: spi@c6000 {
				compatible = "nordic,nrf-spim"; /* in zephyr/dts/vendor/nordic/nrf54l_05_10_15.dtsi:309 */
				#address-cells = < 0x1 >;       /* in zephyr/dts/vendor/nordic/nrf54l_05_10_15.dtsi:310 */
				#size-cells = < 0x0 >;          /* in zephyr/dts/vendor/nordic/nrf54l_05_10_15.dtsi:311 */
				reg = < 0xc6000 0x1000 >;       /* in zephyr/dts/vendor/nordic/nrf54l_05_10_15.dtsi:312 */
				interrupts = < 0xc6 0x1 >;      /* in zephyr/dts/vendor/nordic/nrf54l_05_10_15.dtsi:313 */
				max-frequency = < 0x7a1200 >;   /* in zephyr/dts/vendor/nordic/nrf54l_05_10_15.dtsi:314 */
				easydma-maxcnt-bits = < 0x10 >; /* in zephyr/dts/vendor/nordic/nrf54l_05_10_15.dtsi:315 */
				rx-delay-supported;             /* in zephyr/dts/vendor/nordic/nrf54l_05_10_15.dtsi:316 */
				rx-delay = < 0x1 >;             /* in zephyr/dts/vendor/nordic/nrf54l_05_10_15.dtsi:317 */
				status = "disabled";            /* in zephyr/dts/vendor/nordic/nrf54l_05_10_15.dtsi:318 */
			};

			/* node '/soc/peripheral@50000000/uart@c6000' defined in zephyr/dts/vendor/nordic/nrf54l_05_10_15.dtsi:321 */
			uart20: uart@c6000 {
				compatible = "nordic,nrf-uarte"; /* in zephyr/dts/vendor/nordic/nrf54l_05_10_15.dtsi:322 */
				reg = < 0xc6000 0x1000 >;        /* in zephyr/dts/vendor/nordic/nrf54l_05_10_15.dtsi:323 */
				interrupts = < 0xc6 0x1 >;       /* in zephyr/dts/vendor/nordic/nrf54l_05_10_15.dtsi:324 */
				endtx-stoptx-supported;          /* in zephyr/dts/vendor/nordic/nrf54l_05_10_15.dtsi:326 */
				frame-timeout-supported;         /* in zephyr/dts/vendor/nordic/nrf54l_05_10_15.dtsi:327 */
				current-speed = < 0x1c200 >;     /* in zephyr/boards/seeed/xiao_nrf54l15/xiao_nrf54l15_common.dtsi:38 */
				pinctrl-0 = < &uart20_default >; /* in zephyr/boards/seeed/xiao_nrf54l15/xiao_nrf54l15_common.dtsi:39 */
				pinctrl-1 = < &uart20_sleep >;   /* in zephyr/boards/seeed/xiao_nrf54l15/xiao_nrf54l15_common.dtsi:40 */
				pinctrl-names = "default",
				                "sleep";         /* in zephyr/boards/seeed/xiao_nrf54l15/xiao_nrf54l15_common.dtsi:41 */
				status = "okay";                 /* in zephyr/boards/seeed/xiao_nrf54l15/xiao_nrf54l15_nrf54l15_cpuapp.dts:70 */
			};

			/* node '/soc/peripheral@50000000/i2c@c7000' defined in zephyr/dts/vendor/nordic/nrf54l_05_10_15.dtsi:330 */
			i2c21: i2c@c7000 {
				compatible = "nordic,nrf-twim"; /* in zephyr/dts/vendor/nordic/nrf54l_05_10_15.dtsi:331 */
				#address-cells = < 0x1 >;       /* in zephyr/dts/vendor/nordic/nrf54l_05_10_15.dtsi:332 */
				#size-cells = < 0x0 >;          /* in zephyr/dts/vendor/nordic/nrf54l_05_10_15.dtsi:333 */
				reg = < 0xc7000 0x1000 >;       /* in zephyr/dts/vendor/nordic/nrf54l_05_10_15.dtsi:334 */
				interrupts = < 0xc7 0x1 >;      /* in zephyr/dts/vendor/nordic/nrf54l_05_10_15.dtsi:335 */
				easydma-maxcnt-bits = < 0x10 >; /* in zephyr/dts/vendor/nordic/nrf54l_05_10_15.dtsi:336 */
				status = "disabled";            /* in zephyr/dts/vendor/nordic/nrf54l_05_10_15.dtsi:337 */
				zephyr,pm-device-runtime-auto;  /* in zephyr/dts/vendor/nordic/nrf54l_05_10_15.dtsi:338 */
			};

			/* node '/soc/peripheral@50000000/spi@c7000' defined in zephyr/dts/vendor/nordic/nrf54l_05_10_15.dtsi:341 */
			spi21: spi@c7000 {
				compatible = "nordic,nrf-spim"; /* in zephyr/dts/vendor/nordic/nrf54l_05_10_15.dtsi:348 */
				#address-cells = < 0x1 >;       /* in zephyr/dts/vendor/nordic/nrf54l_05_10_15.dtsi:349 */
				#size-cells = < 0x0 >;          /* in zephyr/dts/vendor/nordic/nrf54l_05_10_15.dtsi:350 */
				reg = < 0xc7000 0x1000 >;       /* in zephyr/dts/vendor/nordic/nrf54l_05_10_15.dtsi:351 */
				interrupts = < 0xc7 0x1 >;      /* in zephyr/dts/vendor/nordic/nrf54l_05_10_15.dtsi:352 */
				max-frequency = < 0x7a1200 >;   /* in zephyr/dts/vendor/nordic/nrf54l_05_10_15.dtsi:353 */
				easydma-maxcnt-bits = < 0x10 >; /* in zephyr/dts/vendor/nordic/nrf54l_05_10_15.dtsi:354 */
				rx-delay-supported;             /* in zephyr/dts/vendor/nordic/nrf54l_05_10_15.dtsi:355 */
				rx-delay = < 0x1 >;             /* in zephyr/dts/vendor/nordic/nrf54l_05_10_15.dtsi:356 */
				status = "disabled";            /* in zephyr/dts/vendor/nordic/nrf54l_05_10_15.dtsi:357 */
			};

			/* node '/soc/peripheral@50000000/uart@c7000' defined in zephyr/dts/vendor/nordic/nrf54l_05_10_15.dtsi:360 */
			uart21: xiao_serial: uart@c7000 {
				compatible = "nordic,nrf-uarte"; /* in zephyr/dts/vendor/nordic/nrf54l_05_10_15.dtsi:361 */
				reg = < 0xc7000 0x1000 >;        /* in zephyr/dts/vendor/nordic/nrf54l_05_10_15.dtsi:362 */
				interrupts = < 0xc7 0x1 >;       /* in zephyr/dts/vendor/nordic/nrf54l_05_10_15.dtsi:363 */
				endtx-stoptx-supported;          /* in zephyr/dts/vendor/nordic/nrf54l_05_10_15.dtsi:365 */
				frame-timeout-supported;         /* in zephyr/dts/vendor/nordic/nrf54l_05_10_15.dtsi:366 */
				current-speed = < 0x1c200 >;     /* in zephyr/boards/seeed/xiao_nrf54l15/xiao_nrf54l15_common.dtsi:45 */
				pinctrl-0 = < &uart21_default >; /* in zephyr/boards/seeed/xiao_nrf54l15/xiao_nrf54l15_common.dtsi:46 */
				pinctrl-1 = < &uart21_sleep >;   /* in zephyr/boards/seeed/xiao_nrf54l15/xiao_nrf54l15_common.dtsi:47 */
				pinctrl-names = "default",
				                "sleep";         /* in zephyr/boards/seeed/xiao_nrf54l15/xiao_nrf54l15_common.dtsi:48 */
				status = "okay";                 /* in zephyr/boards/seeed/xiao_nrf54l15/xiao_nrf54l15_nrf54l15_cpuapp.dts:74 */
			};

			/* node '/soc/peripheral@50000000/i2c@c8000' defined in zephyr/dts/vendor/nordic/nrf54l_05_10_15.dtsi:369 */
			i2c22: xiao_i2c: i2c@c8000 {
				compatible = "nordic,nrf-twim"; /* in zephyr/dts/vendor/nordic/nrf54l_05_10_15.dtsi:370 */
				#address-cells = < 0x1 >;       /* in zephyr/dts/vendor/nordic/nrf54l_05_10_15.dtsi:371 */
				#size-cells = < 0x0 >;          /* in zephyr/dts/vendor/nordic/nrf54l_05_10_15.dtsi:372 */
				reg = < 0xc8000 0x1000 >;       /* in zephyr/dts/vendor/nordic/nrf54l_05_10_15.dtsi:373 */
				interrupts = < 0xc8 0x1 >;      /* in zephyr/dts/vendor/nordic/nrf54l_05_10_15.dtsi:374 */
				easydma-maxcnt-bits = < 0x10 >; /* in zephyr/dts/vendor/nordic/nrf54l_05_10_15.dtsi:375 */
				zephyr,pm-device-runtime-auto;  /* in zephyr/dts/vendor/nordic/nrf54l_05_10_15.dtsi:377 */
				pinctrl-0 = < &i2c22_default >; /* in zephyr/boards/seeed/xiao_nrf54l15/xiao_nrf54l15_common.dtsi:52 */
				pinctrl-1 = < &i2c22_sleep >;   /* in zephyr/boards/seeed/xiao_nrf54l15/xiao_nrf54l15_common.dtsi:53 */
				pinctrl-names = "default",
				                "sleep";        /* in zephyr/boards/seeed/xiao_nrf54l15/xiao_nrf54l15_common.dtsi:54 */
				clock-frequency = < 0x61a80 >;  /* in zephyr/boards/seeed/xiao_nrf54l15/xiao_nrf54l15_common.dtsi:55 */
				status = "okay";                /* in ../../Documents/Projects/PlantSensor/zephyr/boards/xiao_nrf54l15_nrf54l15_cpuapp.overlay:26 */

				/* node '/soc/peripheral@50000000/i2c@c8000/sht4x@44' defined in ../../Documents/Projects/PlantSensor/zephyr/boards/xiao_nrf54l15_nrf54l15_cpuapp.overlay:28 */
				sht4x: sht4x@44 {
					compatible = "sensirion,sht4x"; /* in ../../Documents/Projects/PlantSensor/zephyr/boards/xiao_nrf54l15_nrf54l15_cpuapp.overlay:29 */
					reg = < 0x44 >;                 /* in ../../Documents/Projects/PlantSensor/zephyr/boards/xiao_nrf54l15_nrf54l15_cpuapp.overlay:30 */
					repeatability = < 0x2 >;        /* in ../../Documents/Projects/PlantSensor/zephyr/boards/xiao_nrf54l15_nrf54l15_cpuapp.overlay:31 */
				};

				/* node '/soc/peripheral@50000000/i2c@c8000/bh1750@23' defined in ../../Documents/Projects/PlantSensor/zephyr/boards/xiao_nrf54l15_nrf54l15_cpuapp.overlay:34 */
				bh1750: bh1750@23 {
					compatible = "rohm,bh1750"; /* in ../../Documents/Projects/PlantSensor/zephyr/boards/xiao_nrf54l15_nrf54l15_cpuapp.overlay:35 */
					reg = < 0x23 >;             /* in ../../Documents/Projects/PlantSensor/zephyr/boards/xiao_nrf54l15_nrf54l15_cpuapp.overlay:36 */
				};
			};

			/* node '/soc/peripheral@50000000/spi@c8000' defined in zephyr/dts/vendor/nordic/nrf54l_05_10_15.dtsi:380 */
			spi22: spi@c8000 {
				compatible = "nordic,nrf-spim"; /* in zephyr/dts/vendor/nordic/nrf54l_05_10_15.dtsi:387 */
				#address-cells = < 0x1 >;       /* in zephyr/dts/vendor/nordic/nrf54l_05_10_15.dtsi:388 */
				#size-cells = < 0x0 >;          /* in zephyr/dts/vendor/nordic/nrf54l_05_10_15.dtsi:389 */
				reg = < 0xc8000 0x1000 >;       /* in zephyr/dts/vendor/nordic/nrf54l_05_10_15.dtsi:390 */
				interrupts = < 0xc8 0x1 >;      /* in zephyr/dts/vendor/nordic/nrf54l_05_10_15.dtsi:391 */
				max-frequency = < 0x7a1200 >;   /* in zephyr/dts/vendor/nordic/nrf54l_05_10_15.dtsi:392 */
				easydma-maxcnt-bits = < 0x10 >; /* in zephyr/dts/vendor/nordic/nrf54l_05_10_15.dtsi:393 */
				rx-delay-supported;             /* in zephyr/dts/vendor/nordic/nrf54l_05_10_15.dtsi:394 */
				rx-delay = < 0x1 >;             /* in zephyr/dts/vendor/nordic/nrf54l_05_10_15.dtsi:395 */
				status = "disabled";            /* in zephyr/dts/vendor/nordic/nrf54l_05_10_15.dtsi:396 */
				pinctrl-0 = < &spi22_default >; /* in zephyr/boards/seeed/xiao_nrf54l15/xiao_nrf54l15_common.dtsi:72 */
				pinctrl-1 = < &spi22_sleep >;   /* in zephyr/boards/seeed/xiao_nrf54l15/xiao_nrf54l15_common.dtsi:73 */
				pinctrl-names = "default",
				                "sleep";        /* in zephyr/boards/seeed/xiao_nrf54l15/xiao_nrf54l15_common.dtsi:74 */
			};

			/* node '/soc/peripheral@50000000/uart@c8000' defined in zephyr/dts/vendor/nordic/nrf54l_05_10_15.dtsi:399 */
			uart22: uart@c8000 {
				compatible = "nordic,nrf-uarte"; /* in zephyr/dts/vendor/nordic/nrf54l_05_10_15.dtsi:400 */
				reg = < 0xc8000 0x1000 >;        /* in zephyr/dts/vendor/nordic/nrf54l_05_10_15.dtsi:401 */
				interrupts = < 0xc8 0x1 >;       /* in zephyr/dts/vendor/nordic/nrf54l_05_10_15.dtsi:402 */
				status = "disabled";             /* in zephyr/dts/vendor/nordic/nrf54l_05_10_15.dtsi:403 */
				endtx-stoptx-supported;          /* in zephyr/dts/vendor/nordic/nrf54l_05_10_15.dtsi:404 */
				frame-timeout-supported;         /* in zephyr/dts/vendor/nordic/nrf54l_05_10_15.dtsi:405 */
			};

			/* node '/soc/peripheral@50000000/egu@c9000' defined in zephyr/dts/vendor/nordic/nrf54l_05_10_15.dtsi:408 */
			egu20: egu@c9000 {
				compatible = "nordic,nrf-egu"; /* in zephyr/dts/vendor/nordic/nrf54l_05_10_15.dtsi:409 */
				reg = < 0xc9000 0x1000 >;      /* in zephyr/dts/vendor/nordic/nrf54l_05_10_15.dtsi:410 */
				interrupts = < 0xc9 0x1 >;     /* in zephyr/dts/vendor/nordic/nrf54l_05_10_15.dtsi:411 */
				status = "disabled";           /* in zephyr/dts/vendor/nordic/nrf54l_05_10_15.dtsi:412 */
			};

			/* node '/soc/peripheral@50000000/timer@ca000' defined in zephyr/dts/vendor/nordic/nrf54l_05_10_15.dtsi:415 */
			timer20: timer@ca000 {
				compatible = "nordic,nrf-timer"; /* in zephyr/dts/vendor/nordic/nrf54l_05_10_15.dtsi:416 */
				status = "disabled";             /* in zephyr/dts/vendor/nordic/nrf54l_05_10_15.dtsi:417 */
				reg = < 0xca000 0x1000 >;        /* in zephyr/dts/vendor/nordic/nrf54l_05_10_15.dtsi:418 */
				cc-num = < 0x6 >;                /* in zephyr/dts/vendor/nordic/nrf54l_05_10_15.dtsi:419 */
				max-bit-width = < 0x20 >;        /* in zephyr/dts/vendor/nordic/nrf54l_05_10_15.dtsi:420 */
				interrupts = < 0xca 0x1 >;       /* in zephyr/dts/vendor/nordic/nrf54l_05_10_15.dtsi:421 */
				prescaler = < 0x0 >;             /* in zephyr/dts/vendor/nordic/nrf54l_05_10_15.dtsi:422 */
			};

			/* node '/soc/peripheral@50000000/timer@cb000' defined in zephyr/dts/vendor/nordic/nrf54l_05_10_15.dtsi:425 */
			timer21: timer@cb000 {
				compatible = "nordic,nrf-timer"; /* in zephyr/dts/vendor/nordic/nrf54l_05_10_15.dtsi:426 */
				status = "disabled";             /* in zephyr/dts/vendor/nordic/nrf54l_05_10_15.dtsi:427 */
				reg = < 0xcb000 0x1000 >;        /* in zephyr/dts/vendor/nordic/nrf54l_05_10_15.dtsi:428 */
				cc-num = < 0x6 >;                /* in zephyr/dts/vendor/nordic/nrf54l_05_10_15.dtsi:429 */
				max-bit-width = < 0x20 >;        /* in zephyr/dts/vendor/nordic/nrf54l_05_10_15.dtsi:430 */
				interrupts = < 0xcb 0x1 >;       /* in zephyr/dts/vendor/nordic/nrf54l_05_10_15.dtsi:431 */
				prescaler = < 0x0 >;             /* in zephyr/dts/vendor/nordic/nrf54l_05_10_15.dtsi:432 */
			};

			/* node '/soc/peripheral@50000000/timer@cc000' defined in zephyr/dts/vendor/nordic/nrf54l_05_10_15.dtsi:435 */
			timer22: timer@cc000 {
				compatible = "nordic,nrf-timer"; /* in zephyr/dts/vendor/nordic/nrf54l_05_10_15.dtsi:436 */
				status = "disabled";             /* in zephyr/dts/vendor/nordic/nrf54l_05_10_15.dtsi:437 */
				reg = < 0xcc000 0x1000 >;        /* in zephyr/dts/vendor/nordic/nrf54l_05_10_15.dtsi:438 */
				cc-num = < 0x6 >;                /* in zephyr/dts/vendor/nordic/nrf54l_05_10_15.dtsi:439 */
				max-bit-width = < 0x20 >;        /* in zephyr/dts/vendor/nordic/nrf54l_05_10_15.dtsi:440 */
				interrupts = < 0xcc 0x1 >;       /* in zephyr/dts/vendor/nordic/nrf54l_05_10_15.dtsi:441 */
				prescaler = < 0x0 >;             /* in zephyr/dts/vendor/nordic/nrf54l_05_10_15.dtsi:442 */
			};

			/* node '/soc/peripheral@50000000/timer@cd000' defined in zephyr/dts/vendor/nordic/nrf54l_05_10_15.dtsi:445 */
			timer23: timer@cd000 {
				compatible = "nordic,nrf-timer"; /* in zephyr/dts/vendor/nordic/nrf54l_05_10_15.dtsi:446 */
				status = "disabled";             /* in zephyr/dts/vendor/nordic/nrf54l_05_10_15.dtsi:447 */
				reg = < 0xcd000 0x1000 >;        /* in zephyr/dts/vendor/nordic/nrf54l_05_10_15.dtsi:448 */
				cc-num = < 0x6 >;                /* in zephyr/dts/vendor/nordic/nrf54l_05_10_15.dtsi:449 */
				max-bit-width = < 0x20 >;        /* in zephyr/dts/vendor/nordic/nrf54l_05_10_15.dtsi:450 */
				interrupts = < 0xcd 0x1 >;       /* in zephyr/dts/vendor/nordic/nrf54l_05_10_15.dtsi:451 */
				prescaler = < 0x0 >;             /* in zephyr/dts/vendor/nordic/nrf54l_05_10_15.dtsi:452 */
			};

			/* node '/soc/peripheral@50000000/timer@ce000' defined in zephyr/dts/vendor/nordic/nrf54l_05_10_15.dtsi:455 */
			timer24: timer@ce000 {
				compatible = "nordic,nrf-timer"; /* in zephyr/dts/vendor/nordic/nrf54l_05_10_15.dtsi:456 */
				status = "disabled";             /* in zephyr/dts/vendor/nordic/nrf54l_05_10_15.dtsi:457 */
				reg = < 0xce000 0x1000 >;        /* in zephyr/dts/vendor/nordic/nrf54l_05_10_15.dtsi:458 */
				cc-num = < 0x6 >;                /* in zephyr/dts/vendor/nordic/nrf54l_05_10_15.dtsi:459 */
				max-bit-width = < 0x20 >;        /* in zephyr/dts/vendor/nordic/nrf54l_05_10_15.dtsi:460 */
				interrupts = < 0xce 0x1 >;       /* in zephyr/dts/vendor/nordic/nrf54l_05_10_15.dtsi:461 */
				prescaler = < 0x0 >;             /* in zephyr/dts/vendor/nordic/nrf54l_05_10_15.dtsi:462 */
			};

			/* node '/soc/peripheral@50000000/pdm@d0000' defined in zephyr/dts/vendor/nordic/nrf54l_05_10_15.dtsi:465 */
			pdm20: dmic_dev: pdm@d0000 {
				compatible = "nordic,nrf-pdm";  /* in zephyr/dts/vendor/nordic/nrf54l_05_10_15.dtsi:466 */
				reg = < 0xd0000 0x1000 >;       /* in zephyr/dts/vendor/nordic/nrf54l_05_10_15.dtsi:468 */
				interrupts = < 0xd0 0x1 >;      /* in zephyr/dts/vendor/nordic/nrf54l_05_10_15.dtsi:469 */
				pinctrl-0 = < &pdm20_default >; /* in zephyr/boards/seeed/xiao_nrf54l15/xiao_nrf54l15_common.dtsi:78 */
				pinctrl-names = "default";      /* in zephyr/boards/seeed/xiao_nrf54l15/xiao_nrf54l15_common.dtsi:79 */
				clock-source = "PCLK32M";       /* in zephyr/boards/seeed/xiao_nrf54l15/xiao_nrf54l15_common.dtsi:80 */
				status = "okay";                /* in zephyr/boards/seeed/xiao_nrf54l15/xiao_nrf54l15_nrf54l15_cpuapp.dts:99 */
			};

			/* node '/soc/peripheral@50000000/pdm@d1000' defined in zephyr/dts/vendor/nordic/nrf54l_05_10_15.dtsi:472 */
			pdm21: pdm@d1000 {
				compatible = "nordic,nrf-pdm"; /* in zephyr/dts/vendor/nordic/nrf54l_05_10_15.dtsi:473 */
				status = "disabled";           /* in zephyr/dts/vendor/nordic/nrf54l_05_10_15.dtsi:474 */
				reg = < 0xd1000 0x1000 >;      /* in zephyr/dts/vendor/nordic/nrf54l_05_10_15.dtsi:475 */
				interrupts = < 0xd1 0x1 >;     /* in zephyr/dts/vendor/nordic/nrf54l_05_10_15.dtsi:476 */
			};

			/* node '/soc/peripheral@50000000/pwm@d2000' defined in zephyr/dts/vendor/nordic/nrf54l_05_10_15.dtsi:479 */
			pwm20: pwm@d2000 {
				compatible = "nordic,nrf-pwm"; /* in zephyr/dts/vendor/nordic/nrf54l_05_10_15.dtsi:480 */
				status = "disabled";           /* in zephyr/dts/vendor/nordic/nrf54l_05_10_15.dtsi:481 */
				reg = < 0xd2000 0x1000 >;      /* in zephyr/dts/vendor/nordic/nrf54l_05_10_15.dtsi:482 */
				interrupts = < 0xd2 0x1 >;     /* in zephyr/dts/vendor/nordic/nrf54l_05_10_15.dtsi:483 */
				#pwm-cells = < 0x3 >;          /* in zephyr/dts/vendor/nordic/nrf54l_05_10_15.dtsi:484 */
				idleout-supported;             /* in zephyr/dts/vendor/nordic/nrf54l_05_10_15.dtsi:485 */
			};

			/* node '/soc/peripheral@50000000/pwm@d3000' defined in zephyr/dts/vendor/nordic/nrf54l_05_10_15.dtsi:488 */
			pwm21: pwm@d3000 {
				compatible = "nordic,nrf-pwm"; /* in zephyr/dts/vendor/nordic/nrf54l_05_10_15.dtsi:489 */
				status = "disabled";           /* in zephyr/dts/vendor/nordic/nrf54l_05_10_15.dtsi:490 */
				reg = < 0xd3000 0x1000 >;      /* in zephyr/dts/vendor/nordic/nrf54l_05_10_15.dtsi:491 */
				interrupts = < 0xd3 0x1 >;     /* in zephyr/dts/vendor/nordic/nrf54l_05_10_15.dtsi:492 */
				#pwm-cells = < 0x3 >;          /* in zephyr/dts/vendor/nordic/nrf54l_05_10_15.dtsi:493 */
				idleout-supported;             /* in zephyr/dts/vendor/nordic/nrf54l_05_10_15.dtsi:494 */
			};

			/* node '/soc/peripheral@50000000/pwm@d4000' defined in zephyr/dts/vendor/nordic/nrf54l_05_10_15.dtsi:497 */
			pwm22: pwm@d4000 {
				compatible = "nordic,nrf-pwm"; /* in zephyr/dts/vendor/nordic/nrf54l_05_10_15.dtsi:498 */
				status = "disabled";           /* in zephyr/dts/vendor/nordic/nrf54l_05_10_15.dtsi:499 */
				reg = < 0xd4000 0x1000 >;      /* in zephyr/dts/vendor/nordic/nrf54l_05_10_15.dtsi:500 */
				interrupts = < 0xd4 0x1 >;     /* in zephyr/dts/vendor/nordic/nrf54l_05_10_15.dtsi:501 */
				#pwm-cells = < 0x3 >;          /* in zephyr/dts/vendor/nordic/nrf54l_05_10_15.dtsi:502 */
				idleout-supported;             /* in zephyr/dts/vendor/nordic/nrf54l_05_10_15.dtsi:503 */
			};

			/* node '/soc/peripheral@50000000/adc@d5000' defined in zephyr/dts/vendor/nordic/nrf54l_05_10_15.dtsi:506 */
			adc: xiao_adc: adc@d5000 {
				compatible = "nordic,nrf-saadc"; /* in zephyr/dts/vendor/nordic/nrf54l_05_10_15.dtsi:507 */
				reg = < 0xd5000 0x1000 >;        /* in zephyr/dts/vendor/nordic/nrf54l_05_10_15.dtsi:508 */
				interrupts = < 0xd5 0x1 >;       /* in zephyr/dts/vendor/nordic/nrf54l_05_10_15.dtsi:509 */
				#io-channel-cells = < 0x1 >;     /* in zephyr/dts/vendor/nordic/nrf54l_05_10_15.dtsi:511 */
				zephyr,pm-device-runtime-auto;   /* in zephyr/dts/vendor/nordic/nrf54l_05_10_15.dtsi:512 */
				#address-cells = < 0x1 >;        /* in zephyr/boards/seeed/xiao_nrf54l15/xiao_nrf54l15_common.dtsi:84 */
				#size-cells = < 0x0 >;           /* in zephyr/boards/seeed/xiao_nrf54l15/xiao_nrf54l15_common.dtsi:85 */
				status = "okay";                 /* in zephyr/boards/seeed/xiao_nrf54l15/xiao_nrf54l15_nrf54l15_cpuapp.dts:103 */
				phandle = < 0x18 >;              /* in ../../Documents/Projects/PlantSensor/zephyr/boards/xiao_nrf54l15_nrf54l15_cpuapp.overlay:43 */

				/* node '/soc/peripheral@50000000/adc@d5000/channel@0' defined in zephyr/boards/seeed/xiao_nrf54l15/xiao_nrf54l15_common.dtsi:87 */
				channel@0 {
					reg = < 0x0 >;                         /* in zephyr/boards/seeed/xiao_nrf54l15/xiao_nrf54l15_common.dtsi:88 */
					zephyr,gain = "ADC_GAIN_1_4";          /* in zephyr/boards/seeed/xiao_nrf54l15/xiao_nrf54l15_common.dtsi:89 */
					zephyr,reference = "ADC_REF_INTERNAL"; /* in zephyr/boards/seeed/xiao_nrf54l15/xiao_nrf54l15_common.dtsi:90 */
					zephyr,acquisition-time = < 0x0 >;     /* in zephyr/boards/seeed/xiao_nrf54l15/xiao_nrf54l15_common.dtsi:91 */
					zephyr,input-positive = < 0x0 >;       /* in zephyr/boards/seeed/xiao_nrf54l15/xiao_nrf54l15_common.dtsi:92 */
					zephyr,resolution = < 0xc >;           /* in zephyr/boards/seeed/xiao_nrf54l15/xiao_nrf54l15_common.dtsi:93 */
					zephyr,oversampling = < 0x8 >;         /* in zephyr/boards/seeed/xiao_nrf54l15/xiao_nrf54l15_common.dtsi:94 */
				};

				/* node '/soc/peripheral@50000000/adc@d5000/channel@1' defined in zephyr/boards/seeed/xiao_nrf54l15/xiao_nrf54l15_common.dtsi:97 */
				channel@1 {
					reg = < 0x1 >;                         /* in zephyr/boards/seeed/xiao_nrf54l15/xiao_nrf54l15_common.dtsi:98 */
					zephyr,gain = "ADC_GAIN_1_4";          /* in zephyr/boards/seeed/xiao_nrf54l15/xiao_nrf54l15_common.dtsi:99 */
					zephyr,reference = "ADC_REF_INTERNAL"; /* in zephyr/boards/seeed/xiao_nrf54l15/xiao_nrf54l15_common.dtsi:100 */
					zephyr,acquisition-time = < 0x0 >;     /* in zephyr/boards/seeed/xiao_nrf54l15/xiao_nrf54l15_common.dtsi:101 */
					zephyr,input-positive = < 0x1 >;       /* in zephyr/boards/seeed/xiao_nrf54l15/xiao_nrf54l15_common.dtsi:102 */
					zephyr,resolution = < 0xc >;           /* in zephyr/boards/seeed/xiao_nrf54l15/xiao_nrf54l15_common.dtsi:103 */
					zephyr,oversampling = < 0x8 >;         /* in zephyr/boards/seeed/xiao_nrf54l15/xiao_nrf54l15_common.dtsi:104 */
				};

				/* node '/soc/peripheral@50000000/adc@d5000/channel@2' defined in zephyr/boards/seeed/xiao_nrf54l15/xiao_nrf54l15_common.dtsi:107 */
				channel@2 {
					reg = < 0x2 >;                         /* in zephyr/boards/seeed/xiao_nrf54l15/xiao_nrf54l15_common.dtsi:108 */
					zephyr,gain = "ADC_GAIN_1_4";          /* in zephyr/boards/seeed/xiao_nrf54l15/xiao_nrf54l15_common.dtsi:109 */
					zephyr,reference = "ADC_REF_INTERNAL"; /* in zephyr/boards/seeed/xiao_nrf54l15/xiao_nrf54l15_common.dtsi:110 */
					zephyr,acquisition-time = < 0x0 >;     /* in zephyr/boards/seeed/xiao_nrf54l15/xiao_nrf54l15_common.dtsi:111 */
					zephyr,input-positive = < 0x2 >;       /* in zephyr/boards/seeed/xiao_nrf54l15/xiao_nrf54l15_common.dtsi:112 */
					zephyr,resolution = < 0xc >;           /* in zephyr/boards/seeed/xiao_nrf54l15/xiao_nrf54l15_common.dtsi:113 */
					zephyr,oversampling = < 0x8 >;         /* in zephyr/boards/seeed/xiao_nrf54l15/xiao_nrf54l15_common.dtsi:114 */
				};

				/* node '/soc/peripheral@50000000/adc@d5000/channel@3' defined in zephyr/boards/seeed/xiao_nrf54l15/xiao_nrf54l15_common.dtsi:117 */
				channel@3 {
					reg = < 0x3 >;                         /* in zephyr/boards/seeed/xiao_nrf54l15/xiao_nrf54l15_common.dtsi:118 */
					zephyr,gain = "ADC_GAIN_1_4";          /* in zephyr/boards/seeed/xiao_nrf54l15/xiao_nrf54l15_common.dtsi:119 */
					zephyr,reference = "ADC_REF_INTERNAL"; /* in zephyr/boards/seeed/xiao_nrf54l15/xiao_nrf54l15_common.dtsi:120 */
					zephyr,acquisition-time = < 0x0 >;     /* in zephyr/boards/seeed/xiao_nrf54l15/xiao_nrf54l15_common.dtsi:121 */
					zephyr,input-positive = < 0x3 >;       /* in zephyr/boards/seeed/xiao_nrf54l15/xiao_nrf54l15_common.dtsi:122 */
					zephyr,resolution = < 0xc >;           /* in zephyr/boards/seeed/xiao_nrf54l15/xiao_nrf54l15_common.dtsi:123 */
					zephyr,oversampling = < 0x8 >;         /* in zephyr/boards/seeed/xiao_nrf54l15/xiao_nrf54l15_common.dtsi:124 */
				};

				/* node '/soc/peripheral@50000000/adc@d5000/channel@4' defined in zephyr/boards/seeed/xiao_nrf54l15/xiao_nrf54l15_common.dtsi:127 */
				channel@4 {
					reg = < 0x4 >;                         /* in zephyr/boards/seeed/xiao_nrf54l15/xiao_nrf54l15_common.dtsi:128 */
					zephyr,gain = "ADC_GAIN_1_4";          /* in zephyr/boards/seeed/xiao_nrf54l15/xiao_nrf54l15_common.dtsi:129 */
					zephyr,reference = "ADC_REF_INTERNAL"; /* in zephyr/boards/seeed/xiao_nrf54l15/xiao_nrf54l15_common.dtsi:130 */
					zephyr,acquisition-time = < 0x0 >;     /* in zephyr/boards/seeed/xiao_nrf54l15/xiao_nrf54l15_common.dtsi:131 */
					zephyr,input-positive = < 0x4 >;       /* in zephyr/boards/seeed/xiao_nrf54l15/xiao_nrf54l15_common.dtsi:132 */
					zephyr,resolution = < 0xc >;           /* in zephyr/boards/seeed/xiao_nrf54l15/xiao_nrf54l15_common.dtsi:133 */
					zephyr,oversampling = < 0x8 >;         /* in zephyr/boards/seeed/xiao_nrf54l15/xiao_nrf54l15_common.dtsi:134 */
				};

				/* node '/soc/peripheral@50000000/adc@d5000/channel@5' defined in zephyr/boards/seeed/xiao_nrf54l15/xiao_nrf54l15_common.dtsi:137 */
				channel@5 {
					reg = < 0x5 >;                         /* in zephyr/boards/seeed/xiao_nrf54l15/xiao_nrf54l15_common.dtsi:138 */
					zephyr,gain = "ADC_GAIN_1_4";          /* in zephyr/boards/seeed/xiao_nrf54l15/xiao_nrf54l15_common.dtsi:139 */
					zephyr,reference = "ADC_REF_INTERNAL"; /* in zephyr/boards/seeed/xiao_nrf54l15/xiao_nrf54l15_common.dtsi:140 */
					zephyr,acquisition-time = < 0x0 >;     /* in zephyr/boards/seeed/xiao_nrf54l15/xiao_nrf54l15_common.dtsi:141 */
					zephyr,input-positive = < 0x5 >;       /* in zephyr/boards/seeed/xiao_nrf54l15/xiao_nrf54l15_common.dtsi:142 */
					zephyr,resolution = < 0xc >;           /* in zephyr/boards/seeed/xiao_nrf54l15/xiao_nrf54l15_common.dtsi:143 */
					zephyr,oversampling = < 0x8 >;         /* in zephyr/boards/seeed/xiao_nrf54l15/xiao_nrf54l15_common.dtsi:144 */
				};

				/* node '/soc/peripheral@50000000/adc@d5000/channel@6' defined in zephyr/boards/seeed/xiao_nrf54l15/xiao_nrf54l15_common.dtsi:147 */
				channel@6 {
					reg = < 0x6 >;                         /* in zephyr/boards/seeed/xiao_nrf54l15/xiao_nrf54l15_common.dtsi:148 */
					zephyr,gain = "ADC_GAIN_1_4";          /* in zephyr/boards/seeed/xiao_nrf54l15/xiao_nrf54l15_common.dtsi:149 */
					zephyr,reference = "ADC_REF_INTERNAL"; /* in zephyr/boards/seeed/xiao_nrf54l15/xiao_nrf54l15_common.dtsi:150 */
					zephyr,acquisition-time = < 0x0 >;     /* in zephyr/boards/seeed/xiao_nrf54l15/xiao_nrf54l15_common.dtsi:151 */
					zephyr,input-positive = < 0x6 >;       /* in zephyr/boards/seeed/xiao_nrf54l15/xiao_nrf54l15_common.dtsi:152 */
					zephyr,resolution = < 0xc >;           /* in zephyr/boards/seeed/xiao_nrf54l15/xiao_nrf54l15_common.dtsi:153 */
					zephyr,oversampling = < 0x8 >;         /* in zephyr/boards/seeed/xiao_nrf54l15/xiao_nrf54l15_common.dtsi:154 */
				};

				/* node '/soc/peripheral@50000000/adc@d5000/channel@7' defined in zephyr/boards/seeed/xiao_nrf54l15/xiao_nrf54l15_common.dtsi:157 */
				channel@7 {
					reg = < 0x7 >;                         /* in zephyr/boards/seeed/xiao_nrf54l15/xiao_nrf54l15_common.dtsi:158 */
					zephyr,gain = "ADC_GAIN_1_4";          /* in zephyr/boards/seeed/xiao_nrf54l15/xiao_nrf54l15_common.dtsi:159 */
					zephyr,reference = "ADC_REF_INTERNAL"; /* in zephyr/boards/seeed/xiao_nrf54l15/xiao_nrf54l15_common.dtsi:160 */
					zephyr,acquisition-time = < 0x0 >;     /* in zephyr/boards/seeed/xiao_nrf54l15/xiao_nrf54l15_common.dtsi:161 */
					zephyr,input-positive = < 0x7 >;       /* in zephyr/boards/seeed/xiao_nrf54l15/xiao_nrf54l15_common.dtsi:162 */
					zephyr,resolution = < 0xc >;           /* in zephyr/boards/seeed/xiao_nrf54l15/xiao_nrf54l15_common.dtsi:163 */
					zephyr,oversampling = < 0x8 >;         /* in zephyr/boards/seeed/xiao_nrf54l15/xiao_nrf54l15_common.dtsi:164 */
				};
			};

			/* node '/soc/peripheral@50000000/nfct@d6000' defined in zephyr/dts/vendor/nordic/nrf54l_05_10_15.dtsi:515 */
			nfct: nfct@d6000 {
				compatible = "nordic,nrf-nfct"; /* in zephyr/dts/vendor/nordic/nrf54l_05_10_15.dtsi:516 */
				reg = < 0xd6000 0x1000 >;       /* in zephyr/dts/vendor/nordic/nrf54l_05_10_15.dtsi:517 */
				interrupts = < 0xd6 0x1 >;      /* in zephyr/dts/vendor/nordic/nrf54l_05_10_15.dtsi:518 */
				status = "disabled";            /* in zephyr/dts/vendor/nordic/nrf54l_05_10_15.dtsi:519 */
			};

			/* node '/soc/peripheral@50000000/temp@d7000' defined in zephyr/dts/vendor/nordic/nrf54l_05_10_15.dtsi:522 */
			temp: temp@d7000 {
				compatible = "nordic,nrf-temp"; /* in zephyr/dts/vendor/nordic/nrf54l_05_10_15.dtsi:523 */
				reg = < 0xd7000 0x1000 >;       /* in zephyr/dts/vendor/nordic/nrf54l_05_10_15.dtsi:524 */
				interrupts = < 0xd7 0x1 >;      /* in zephyr/dts/vendor/nordic/nrf54l_05_10_15.dtsi:525 */
				status = "disabled";            /* in zephyr/dts/vendor/nordic/nrf54l_05_10_15.dtsi:526 */
			};

			/* node '/soc/peripheral@50000000/gpio@d8200' defined in zephyr/dts/vendor/nordic/nrf54l_05_10_15.dtsi:529 */
			gpio1: gpio@d8200 {
				compatible = "nordic,nrf-gpio";  /* in zephyr/dts/vendor/nordic/nrf54l_05_10_15.dtsi:530 */
				gpio-controller;                 /* in zephyr/dts/vendor/nordic/nrf54l_05_10_15.dtsi:531 */
				reg = < 0xd8200 0x300 >;         /* in zephyr/dts/vendor/nordic/nrf54l_05_10_15.dtsi:532 */
				#gpio-cells = < 0x2 >;           /* in zephyr/dts/vendor/nordic/nrf54l_05_10_15.dtsi:533 */
				ngpios = < 0x10 >;               /* in zephyr/dts/vendor/nordic/nrf54l_05_10_15.dtsi:534 */
				port = < 0x1 >;                  /* in zephyr/dts/vendor/nordic/nrf54l_05_10_15.dtsi:536 */
				gpiote-instance = < &gpiote20 >; /* in zephyr/dts/vendor/nordic/nrf54l_05_10_15.dtsi:537 */
				status = "okay";                 /* in zephyr/boards/seeed/xiao_nrf54l15/xiao_nrf54l15_nrf54l15_cpuapp.dts:117 */
				phandle = < 0x16 >;              /* in zephyr/boards/seeed/xiao_nrf54l15/seeed_xiao_connector.dtsi:11 */
			};

			/* node '/soc/peripheral@50000000/gpiote@da000' defined in zephyr/dts/vendor/nordic/nrf54l_05_10_15.dtsi:540 */
			gpiote20: gpiote@da000 {
				compatible = "nordic,nrf-gpiote"; /* in zephyr/dts/vendor/nordic/nrf54l_05_10_15.dtsi:541 */
				reg = < 0xda000 0x1000 >;         /* in zephyr/dts/vendor/nordic/nrf54l_05_10_15.dtsi:542 */
				instance = < 0x14 >;              /* in zephyr/dts/vendor/nordic/nrf54l_05_10_15.dtsi:544 */
				interrupts = < 0xdb 0x1 >;        /* in zephyr/dts/arm/nordic/nrf54l_05_10_15_cpuapp.dtsi:84 */
				status = "okay";                  /* in zephyr/boards/seeed/xiao_nrf54l15/xiao_nrf54l15_nrf54l15_cpuapp.dts:125 */
				phandle = < 0xf >;                /* in zephyr/dts/vendor/nordic/nrf54l_05_10_15.dtsi:537 */
			};

			/* node '/soc/peripheral@50000000/i2s@dd000' defined in zephyr/dts/vendor/nordic/nrf54l_05_10_15.dtsi:547 */
			i2s20: i2s@dd000 {
				compatible = "nordic,nrf-i2s"; /* in zephyr/dts/vendor/nordic/nrf54l_05_10_15.dtsi:548 */
				#address-cells = < 0x1 >;      /* in zephyr/dts/vendor/nordic/nrf54l_05_10_15.dtsi:549 */
				#size-cells = < 0x0 >;         /* in zephyr/dts/vendor/nordic/nrf54l_05_10_15.dtsi:550 */
				reg = < 0xdd000 0x1000 >;      /* in zephyr/dts/vendor/nordic/nrf54l_05_10_15.dtsi:551 */
				interrupts = < 0xdd 0x1 >;     /* in zephyr/dts/vendor/nordic/nrf54l_05_10_15.dtsi:552 */
				status = "disabled";           /* in zephyr/dts/vendor/nordic/nrf54l_05_10_15.dtsi:553 */
			};

			/* node '/soc/peripheral@50000000/qdec@e0000' defined in zephyr/dts/vendor/nordic/nrf54l_05_10_15.dtsi:556 */
			qdec20: qdec@e0000 {
				compatible = "nordic,nrf-qdec"; /* in zephyr/dts/vendor/nordic/nrf54l_05_10_15.dtsi:557 */
				reg = < 0xe0000 0x1000 >;       /* in zephyr/dts/vendor/nordic/nrf54l_05_10_15.dtsi:558 */
				interrupts = < 0xe0 0x1 >;      /* in zephyr/dts/vendor/nordic/nrf54l_05_10_15.dtsi:559 */
				status = "disabled";            /* in zephyr/dts/vendor/nordic/nrf54l_05_10_15.dtsi:560 */
			};

			/* node '/soc/peripheral@50000000/qdec@e1000' defined in zephyr/dts/vendor/nordic/nrf54l_05_10_15.dtsi:563 */
			qdec21: qdec@e1000 {
				compatible = "nordic,nrf-qdec"; /* in zephyr/dts/vendor/nordic/nrf54l_05_10_15.dtsi:564 */
				reg = < 0xe1000 0x1000 >;       /* in zephyr/dts/vendor/nordic/nrf54l_05_10_15.dtsi:565 */
				interrupts = < 0xe1 0x1 >;      /* in zephyr/dts/vendor/nordic/nrf54l_05_10_15.dtsi:566 */
				status = "disabled";            /* in zephyr/dts/vendor/nordic/nrf54l_05_10_15.dtsi:567 */
			};

			/* node '/soc/peripheral@50000000/grtc@e2000' defined in zephyr/dts/vendor/nordic/nrf54l_05_10_15.dtsi:570 */
			grtc: grtc@e2000 {
				compatible = "nordic,nrf-grtc";                                       /* in zephyr/dts/vendor/nordic/nrf54l_05_10_15.dtsi:571 */
				reg = < 0xe2000 0x1000 >;                                             /* in zephyr/dts/vendor/nordic/nrf54l_05_10_15.dtsi:572 */
				cc-num = < 0xc >;                                                     /* in zephyr/dts/vendor/nordic/nrf54l_05_10_15.dtsi:573 */
				clocks = < &lfxo >,
				         < &pclk >;                                                   /* in zephyr/dts/vendor/nordic/nrf54l_05_10_15.dtsi:574 */
				clock-names = "lfclock",
				              "hfclock";                                              /* in zephyr/dts/vendor/nordic/nrf54l_05_10_15.dtsi:575 */
				interrupts = < 0xe4 0x1 >,
				             < 0xe5 0x1 >;                                            /* in zephyr/dts/arm/nordic/nrf54l_05_10_15_cpuapp.dtsi:75 */
				owned-channels = < 0x0 0x1 0x2 0x3 0x4 0x5 0x6 0x7 0x8 0x9 0xa 0xb >; /* in zephyr/boards/seeed/xiao_nrf54l15/xiao_nrf54l15_nrf54l15_cpuapp.dts:59 */
				child-owned-channels = < 0x3 0x4 0x7 0x8 0x9 0xa 0xb >;               /* in zephyr/boards/seeed/xiao_nrf54l15/xiao_nrf54l15_nrf54l15_cpuapp.dts:61 */
				status = "okay";                                                      /* in zephyr/boards/seeed/xiao_nrf54l15/xiao_nrf54l15_nrf54l15_cpuapp.dts:62 */
			};

			/* node '/soc/peripheral@50000000/dppic@102000' defined in zephyr/dts/vendor/nordic/nrf54l_05_10_15.dtsi:579 */
			dppic30: dppic@102000 {
				compatible = "nordic,nrf-dppic"; /* in zephyr/dts/vendor/nordic/nrf54l_05_10_15.dtsi:580 */
				reg = < 0x102000 0x808 >;        /* in zephyr/dts/vendor/nordic/nrf54l_05_10_15.dtsi:581 */
				status = "okay";                 /* in zephyr/dts/arm/nordic/nrf54l_05_10_15_cpuapp.dtsi:109 */
			};

			/* node '/soc/peripheral@50000000/ppib@103000' defined in zephyr/dts/vendor/nordic/nrf54l_05_10_15.dtsi:585 */
			ppib30: ppib@103000 {
				compatible = "nordic,nrf-ppib"; /* in zephyr/dts/vendor/nordic/nrf54l_05_10_15.dtsi:586 */
				reg = < 0x103000 0x1000 >;      /* in zephyr/dts/vendor/nordic/nrf54l_05_10_15.dtsi:587 */
				status = "okay";                /* in zephyr/dts/arm/nordic/nrf54l_05_10_15_cpuapp.dtsi:141 */
			};

			/* node '/soc/peripheral@50000000/i2c@104000' defined in zephyr/dts/vendor/nordic/nrf54l_05_10_15.dtsi:591 */
			i2c30: i2c@104000 {
				compatible = "nordic,nrf-twim"; /* in zephyr/dts/vendor/nordic/nrf54l_05_10_15.dtsi:592 */
				#address-cells = < 0x1 >;       /* in zephyr/dts/vendor/nordic/nrf54l_05_10_15.dtsi:593 */
				#size-cells = < 0x0 >;          /* in zephyr/dts/vendor/nordic/nrf54l_05_10_15.dtsi:594 */
				reg = < 0x104000 0x1000 >;      /* in zephyr/dts/vendor/nordic/nrf54l_05_10_15.dtsi:595 */
				interrupts = < 0x104 0x1 >;     /* in zephyr/dts/vendor/nordic/nrf54l_05_10_15.dtsi:596 */
				easydma-maxcnt-bits = < 0x10 >; /* in zephyr/dts/vendor/nordic/nrf54l_05_10_15.dtsi:597 */
				zephyr,pm-device-runtime-auto;  /* in zephyr/dts/vendor/nordic/nrf54l_05_10_15.dtsi:599 */
				pinctrl-0 = < &i2c30_default >; /* in zephyr/boards/seeed/xiao_nrf54l15/xiao_nrf54l15_common.dtsi:59 */
				pinctrl-1 = < &i2c30_sleep >;   /* in zephyr/boards/seeed/xiao_nrf54l15/xiao_nrf54l15_common.dtsi:60 */
				pinctrl-names = "default",
				                "sleep";        /* in zephyr/boards/seeed/xiao_nrf54l15/xiao_nrf54l15_common.dtsi:61 */
				clock-frequency = < 0x61a80 >;  /* in zephyr/boards/seeed/xiao_nrf54l15/xiao_nrf54l15_common.dtsi:62 */
				status = "okay";                /* in zephyr/boards/seeed/xiao_nrf54l15/xiao_nrf54l15_nrf54l15_cpuapp.dts:82 */

				/* node '/soc/peripheral@50000000/i2c@104000/lsm6dso@6a' defined in zephyr/boards/seeed/xiao_nrf54l15/xiao_nrf54l15_nrf54l15_cpuapp.dts:84 */
				lsm6dso: lsm6dso@6a {
					compatible = "st,lsm6dso";      /* in zephyr/boards/seeed/xiao_nrf54l15/xiao_nrf54l15_nrf54l15_cpuapp.dts:85 */
					reg = < 0x6a >;                 /* in zephyr/boards/seeed/xiao_nrf54l15/xiao_nrf54l15_nrf54l15_cpuapp.dts:86 */
					irq-gpios = < &gpio0 0x2 0x0 >; /* in zephyr/boards/seeed/xiao_nrf54l15/xiao_nrf54l15_nrf54l15_cpuapp.dts:87 */
					accel-pm = < 0x2 >;             /* in zephyr/boards/seeed/xiao_nrf54l15/xiao_nrf54l15_nrf54l15_cpuapp.dts:88 */
					gyro-pm = < 0x1 >;              /* in zephyr/boards/seeed/xiao_nrf54l15/xiao_nrf54l15_nrf54l15_cpuapp.dts:89 */
					status = "okay";                /* in zephyr/boards/seeed/xiao_nrf54l15/xiao_nrf54l15_nrf54l15_cpuapp.dts:90 */
				};
			};

			/* node '/soc/peripheral@50000000/spi@104000' defined in zephyr/dts/vendor/nordic/nrf54l_05_10_15.dtsi:602 */
			spi30: spi@104000 {
				compatible = "nordic,nrf-spim"; /* in zephyr/dts/vendor/nordic/nrf54l_05_10_15.dtsi:609 */
				#address-cells = < 0x1 >;       /* in zephyr/dts/vendor/nordic/nrf54l_05_10_15.dtsi:610 */
				#size-cells = < 0x0 >;          /* in zephyr/dts/vendor/nordic/nrf54l_05_10_15.dtsi:611 */
				reg = < 0x104000 0x1000 >;      /* in zephyr/dts/vendor/nordic/nrf54l_05_10_15.dtsi:612 */
				interrupts = < 0x104 0x1 >;     /* in zephyr/dts/vendor/nordic/nrf54l_05_10_15.dtsi:613 */
				max-frequency = < 0x7a1200 >;   /* in zephyr/dts/vendor/nordic/nrf54l_05_10_15.dtsi:614 */
				easydma-maxcnt-bits = < 0x10 >; /* in zephyr/dts/vendor/nordic/nrf54l_05_10_15.dtsi:615 */
				rx-delay-supported;             /* in zephyr/dts/vendor/nordic/nrf54l_05_10_15.dtsi:616 */
				rx-delay = < 0x1 >;             /* in zephyr/dts/vendor/nordic/nrf54l_05_10_15.dtsi:617 */
				status = "disabled";            /* in zephyr/dts/vendor/nordic/nrf54l_05_10_15.dtsi:618 */
			};

			/* node '/soc/peripheral@50000000/uart@104000' defined in zephyr/dts/vendor/nordic/nrf54l_05_10_15.dtsi:621 */
			uart30: uart@104000 {
				compatible = "nordic,nrf-uarte"; /* in zephyr/dts/vendor/nordic/nrf54l_05_10_15.dtsi:622 */
				reg = < 0x104000 0x1000 >;       /* in zephyr/dts/vendor/nordic/nrf54l_05_10_15.dtsi:623 */
				interrupts = < 0x104 0x1 >;      /* in zephyr/dts/vendor/nordic/nrf54l_05_10_15.dtsi:624 */
				status = "disabled";             /* in zephyr/dts/vendor/nordic/nrf54l_05_10_15.dtsi:625 */
				endtx-stoptx-supported;          /* in zephyr/dts/vendor/nordic/nrf54l_05_10_15.dtsi:626 */
				frame-timeout-supported;         /* in zephyr/dts/vendor/nordic/nrf54l_05_10_15.dtsi:627 */
			};

			/* node '/soc/peripheral@50000000/clock@10e000' defined in zephyr/dts/vendor/nordic/nrf54l_05_10_15.dtsi:630 */
			clock: clock@10e000 {
				compatible = "nordic,nrf-clock"; /* in zephyr/dts/vendor/nordic/nrf54l_05_10_15.dtsi:631 */
				reg = < 0x10e000 0x1000 >;       /* in zephyr/dts/vendor/nordic/nrf54l_05_10_15.dtsi:632 */
				interrupts = < 0x105 0x1 >;      /* in zephyr/dts/vendor/nordic/nrf54l_05_10_15.dtsi:633 */
				status = "okay";                 /* in zephyr/boards/seeed/xiao_nrf54l15/xiao_nrf54l15_nrf54l15_cpuapp.dts:66 */
			};

			/* node '/soc/peripheral@50000000/power@10e000' defined in zephyr/dts/vendor/nordic/nrf54l_05_10_15.dtsi:637 */
			power: power@10e000 {
				compatible = "nordic,nrf-power";  /* in zephyr/dts/vendor/nordic/nrf54l_05_10_15.dtsi:638 */
				reg = < 0x10e000 0x1000 >;        /* in zephyr/dts/vendor/nordic/nrf54l_05_10_15.dtsi:639 */
				ranges = < 0x0 0x10e000 0x1000 >; /* in zephyr/dts/vendor/nordic/nrf54l_05_10_15.dtsi:640 */
				interrupts = < 0x105 0x1 >;       /* in zephyr/dts/vendor/nordic/nrf54l_05_10_15.dtsi:641 */
				status = "disabled";              /* in zephyr/dts/vendor/nordic/nrf54l_05_10_15.dtsi:642 */
				#address-cells = < 0x1 >;         /* in zephyr/dts/vendor/nordic/nrf54l_05_10_15.dtsi:643 */
				#size-cells = < 0x1 >;            /* in zephyr/dts/vendor/nordic/nrf54l_05_10_15.dtsi:644 */

				/* node '/soc/peripheral@50000000/power@10e000/gpregret1@500' defined in zephyr/dts/vendor/nordic/nrf54l_05_10_15.dtsi:646 */
				gpregret1: gpregret1@500 {
					#address-cells = < 0x1 >;           /* in zephyr/dts/vendor/nordic/nrf54l_05_10_15.dtsi:647 */
					#size-cells = < 0x1 >;              /* in zephyr/dts/vendor/nordic/nrf54l_05_10_15.dtsi:648 */
					compatible = "nordic,nrf-gpregret"; /* in zephyr/dts/vendor/nordic/nrf54l_05_10_15.dtsi:649 */
					reg = < 0x500 0x1 >;                /* in zephyr/dts/vendor/nordic/nrf54l_05_10_15.dtsi:650 */
					status = "disabled";                /* in zephyr/dts/vendor/nordic/nrf54l_05_10_15.dtsi:651 */
				};

				/* node '/soc/peripheral@50000000/power@10e000/gpregret2@504' defined in zephyr/dts/vendor/nordic/nrf54l_05_10_15.dtsi:654 */
				gpregret2: gpregret2@504 {
					#address-cells = < 0x1 >;           /* in zephyr/dts/vendor/nordic/nrf54l_05_10_15.dtsi:655 */
					#size-cells = < 0x1 >;              /* in zephyr/dts/vendor/nordic/nrf54l_05_10_15.dtsi:656 */
					compatible = "nordic,nrf-gpregret"; /* in zephyr/dts/vendor/nordic/nrf54l_05_10_15.dtsi:657 */
					reg = < 0x504 0x1 >;                /* in zephyr/dts/vendor/nordic/nrf54l_05_10_15.dtsi:658 */
					status = "disabled";                /* in zephyr/dts/vendor/nordic/nrf54l_05_10_15.dtsi:659 */
				};
			};

			/* node '/soc/peripheral@50000000/comparator@106000' defined in zephyr/dts/vendor/nordic/nrf54l_05_10_15.dtsi:663 */
			comp: comparator@106000 {
				compatible = "nordic,nrf-comp"; /* in zephyr/dts/vendor/nordic/nrf54l_05_10_15.dtsi:668 */
				reg = < 0x106000 0x1000 >;      /* in zephyr/dts/vendor/nordic/nrf54l_05_10_15.dtsi:669 */
				status = "disabled";            /* in zephyr/dts/vendor/nordic/nrf54l_05_10_15.dtsi:670 */
				interrupts = < 0x106 0x1 >;     /* in zephyr/dts/vendor/nordic/nrf54l_05_10_15.dtsi:671 */
			};

			/* node '/soc/peripheral@50000000/watchdog@108000' defined in zephyr/dts/vendor/nordic/nrf54l_05_10_15.dtsi:677 */
			wdt30: watchdog@108000 {
				compatible = "nordic,nrf-wdt"; /* in zephyr/dts/vendor/nordic/nrf54l_05_10_15.dtsi:678 */
				reg = < 0x108000 0x620 >;      /* in zephyr/dts/vendor/nordic/nrf54l_05_10_15.dtsi:679 */
				interrupts = < 0x108 0x1 >;    /* in zephyr/dts/vendor/nordic/nrf54l_05_10_15.dtsi:680 */
				status = "disabled";           /* in zephyr/dts/vendor/nordic/nrf54l_05_10_15.dtsi:681 */
			};

			/* node '/soc/peripheral@50000000/watchdog@109000' defined in zephyr/dts/vendor/nordic/nrf54l_05_10_15.dtsi:685 */
			wdt31: watchdog@109000 {
				compatible = "nordic,nrf-wdt"; /* in zephyr/dts/vendor/nordic/nrf54l_05_10_15.dtsi:686 */
				reg = < 0x109000 0x620 >;      /* in zephyr/dts/vendor/nordic/nrf54l_05_10_15.dtsi:687 */
				interrupts = < 0x109 0x1 >;    /* in zephyr/dts/vendor/nordic/nrf54l_05_10_15.dtsi:688 */
				status = "disabled";           /* in zephyr/dts/vendor/nordic/nrf54l_05_10_15.dtsi:689 */
			};

			/* node '/soc/peripheral@50000000/gpio@10a000' defined in zephyr/dts/vendor/nordic/nrf54l_05_10_15.dtsi:692 */
			gpio0: gpio@10a000 {
				compatible = "nordic,nrf-gpio";  /* in zephyr/dts/vendor/nordic/nrf54l_05_10_15.dtsi:693 */
				gpio-controller;                 /* in zephyr/dts/vendor/nordic/nrf54l_05_10_15.dtsi:694 */
				reg = < 0x10a000 0x300 >;        /* in zephyr/dts/vendor/nordic/nrf54l_05_10_15.dtsi:695 */
				#gpio-cells = < 0x2 >;           /* in zephyr/dts/vendor/nordic/nrf54l_05_10_15.dtsi:696 */
				ngpios = < 0x5 >;                /* in zephyr/dts/vendor/nordic/nrf54l_05_10_15.dtsi:697 */
				port = < 0x0 >;                  /* in zephyr/dts/vendor/nordic/nrf54l_05_10_15.dtsi:699 */
				gpiote-instance = < &gpiote30 >; /* in zephyr/dts/vendor/nordic/nrf54l_05_10_15.dtsi:700 */
				status = "okay";                 /* in zephyr/boards/seeed/xiao_nrf54l15/xiao_nrf54l15_nrf54l15_cpuapp.dts:107 */
				phandle = < 0x14 >;              /* in zephyr/boards/seeed/xiao_nrf54l15/xiao_nrf54l15_nrf54l15_cpuapp.dts:87 */

				/* node '/soc/peripheral@50000000/gpio@10a000/imu_power_default_on' defined in zephyr/boards/seeed/xiao_nrf54l15/xiao_nrf54l15_nrf54l15_cpuapp.dts:109 */
				imu_power_default_on: imu_power_default_on {
					gpio-hog;                       /* in zephyr/boards/seeed/xiao_nrf54l15/xiao_nrf54l15_nrf54l15_cpuapp.dts:110 */
					gpios = < 0x1 0x0 >;            /* in zephyr/boards/seeed/xiao_nrf54l15/xiao_nrf54l15_nrf54l15_cpuapp.dts:111 */
					line-name = "imu-power-enable"; /* in zephyr/boards/seeed/xiao_nrf54l15/xiao_nrf54l15_nrf54l15_cpuapp.dts:112 */
				};
			};

			/* node '/soc/peripheral@50000000/gpiote@10c000' defined in zephyr/dts/vendor/nordic/nrf54l_05_10_15.dtsi:703 */
			gpiote30: gpiote@10c000 {
				compatible = "nordic,nrf-gpiote"; /* in zephyr/dts/vendor/nordic/nrf54l_05_10_15.dtsi:704 */
				reg = < 0x10c000 0x1000 >;        /* in zephyr/dts/vendor/nordic/nrf54l_05_10_15.dtsi:705 */
				instance = < 0x1e >;              /* in zephyr/dts/vendor/nordic/nrf54l_05_10_15.dtsi:707 */
				interrupts = < 0x10d 0x1 >;       /* in zephyr/dts/arm/nordic/nrf54l_05_10_15_cpuapp.dtsi:92 */
				status = "okay";                  /* in zephyr/boards/seeed/xiao_nrf54l15/xiao_nrf54l15_nrf54l15_cpuapp.dts:129 */
				phandle = < 0x15 >;               /* in zephyr/dts/vendor/nordic/nrf54l_05_10_15.dtsi:700 */
			};

			/* node '/soc/peripheral@50000000/regulator@120000' defined in zephyr/dts/vendor/nordic/nrf54l_05_10_15.dtsi:710 */
			regulators: regulator@120000 {
				compatible = "nordic,nrf54l-regulators"; /* in zephyr/dts/vendor/nordic/nrf54l_05_10_15.dtsi:711 */
				reg = < 0x120000 0x1000 >;               /* in zephyr/dts/vendor/nordic/nrf54l_05_10_15.dtsi:712 */
				#address-cells = < 0x1 >;                /* in zephyr/dts/vendor/nordic/nrf54l_05_10_15.dtsi:714 */
				#size-cells = < 0x1 >;                   /* in zephyr/dts/vendor/nordic/nrf54l_05_10_15.dtsi:715 */
				status = "okay";                         /* in zephyr/boards/seeed/xiao_nrf54l15/xiao_nrf54l15_nrf54l15_cpuapp.dts:133 */

				/* node '/soc/peripheral@50000000/regulator@120000/regulator@120600' defined in zephyr/dts/vendor/nordic/nrf54l_05_10_15.dtsi:717 */
				vregmain: regulator@120600 {
					compatible = "nordic,nrf5x-regulator"; /* in zephyr/dts/vendor/nordic/nrf54l_05_10_15.dtsi:718 */
					reg = < 0x120600 0x1 >;                /* in zephyr/dts/vendor/nordic/nrf54l_05_10_15.dtsi:719 */
					regulator-name = "VREGMAIN";           /* in zephyr/dts/vendor/nordic/nrf54l_05_10_15.dtsi:721 */
					status = "okay";                       /* in zephyr/boards/seeed/xiao_nrf54l15/xiao_nrf54l15_nrf54l15_cpuapp.dts:137 */
					regulator-initial-mode = < 0x1 >;      /* in zephyr/boards/seeed/xiao_nrf54l15/xiao_nrf54l15_nrf54l15_cpuapp.dts:138 */
				};
			};
		};

		/* node '/soc/rram-controller@5004b000' defined in zephyr/dts/vendor/nordic/nrf54l_05_10_15.dtsi:727 */
		rram_controller: rram-controller@5004b000 {
			compatible = "nordic,rram-controller"; /* in zephyr/dts/vendor/nordic/nrf54l_05_10_15.dtsi:728 */
			reg = < 0x5004b000 0x1000 >;           /* in zephyr/dts/vendor/nordic/nrf54l_05_10_15.dtsi:729 */
			#address-cells = < 0x1 >;              /* in zephyr/dts/vendor/nordic/nrf54l_05_10_15.dtsi:730 */
			#size-cells = < 0x1 >;                 /* in zephyr/dts/vendor/nordic/nrf54l_05_10_15.dtsi:731 */
			interrupts = < 0x4b 0x1 >;             /* in zephyr/dts/vendor/nordic/nrf54l_05_10_15.dtsi:732 */

			/* node '/soc/rram-controller@5004b000/rram@0' defined in zephyr/dts/vendor/nordic/nrf54l_05_10_15.dtsi:734 */
			cpuapp_rram: rram@0 {
				compatible = "soc-nv-flash";   /* in zephyr/dts/vendor/nordic/nrf54l_05_10_15.dtsi:735 */
				erase-block-size = < 0x1000 >; /* in zephyr/dts/vendor/nordic/nrf54l_05_10_15.dtsi:736 */
				write-block-size = < 0x10 >;   /* in zephyr/dts/vendor/nordic/nrf54l_05_10_15.dtsi:737 */
				reg = < 0x0 0x165000 >;        /* in zephyr/dts/vendor/nordic/nrf54l15.dtsi:28 */

				/* node '/soc/rram-controller@5004b000/rram@0/partitions' defined in zephyr/dts/vendor/nordic/nrf54l15_partition.dtsi:8 */
				partitions {
					compatible = "fixed-partitions"; /* in zephyr/dts/vendor/nordic/nrf54l15_partition.dtsi:9 */
					#address-cells = < 0x1 >;        /* in zephyr/dts/vendor/nordic/nrf54l15_partition.dtsi:10 */
					#size-cells = < 0x1 >;           /* in zephyr/dts/vendor/nordic/nrf54l15_partition.dtsi:11 */

					/* node '/soc/rram-controller@5004b000/rram@0/partitions/partition@0' defined in zephyr/dts/vendor/nordic/nrf54l15_partition.dtsi:13 */
					boot_partition: partition@0 {
						label = "mcuboot";     /* in zephyr/dts/vendor/nordic/nrf54l15_partition.dtsi:14 */
						reg = < 0x0 0x10000 >; /* in zephyr/dts/vendor/nordic/nrf54l15_partition.dtsi:15 */
					};

					/* node '/soc/rram-controller@5004b000/rram@0/partitions/partition@10000' defined in zephyr/dts/vendor/nordic/nrf54l15_partition.dtsi:18 */
					slot0_partition: partition@10000 {
						label = "image-0";         /* in zephyr/dts/vendor/nordic/nrf54l15_partition.dtsi:19 */
						reg = < 0x10000 0xa6000 >; /* in zephyr/dts/vendor/nordic/nrf54l15_partition.dtsi:20 */
					};

					/* node '/soc/rram-controller@5004b000/rram@0/partitions/partition@b6000' defined in zephyr/dts/vendor/nordic/nrf54l15_partition.dtsi:23 */
					slot1_partition: partition@b6000 {
						label = "image-1";         /* in zephyr/dts/vendor/nordic/nrf54l15_partition.dtsi:24 */
						reg = < 0xb6000 0xa6000 >; /* in zephyr/dts/vendor/nordic/nrf54l15_partition.dtsi:25 */
					};

					/* node '/soc/rram-controller@5004b000/rram@0/partitions/partition@15c000' defined in zephyr/dts/vendor/nordic/nrf54l15_partition.dtsi:28 */
					storage_partition: partition@15c000 {
						label = "storage";         /* in zephyr/dts/vendor/nordic/nrf54l15_partition.dtsi:29 */
						reg = < 0x15c000 0x9000 >; /* in zephyr/dts/vendor/nordic/nrf54l15_partition.dtsi:30 */
					};
				};
			};
		};

		/* node '/soc/memory@50041000' defined in zephyr/dts/vendor/nordic/nrf54l_05_10_15.dtsi:741 */
		nrf_mpc: memory@50041000 {
			compatible = "nordic,nrf-mpc";     /* in zephyr/dts/vendor/nordic/nrf54l_05_10_15.dtsi:742 */
			reg = < 0x50041000 0x1000 >;       /* in zephyr/dts/vendor/nordic/nrf54l_05_10_15.dtsi:743 */
			#address-cells = < 0x1 >;          /* in zephyr/dts/vendor/nordic/nrf54l_05_10_15.dtsi:744 */
			#size-cells = < 0x1 >;             /* in zephyr/dts/vendor/nordic/nrf54l_05_10_15.dtsi:745 */
			override-num = < 0x5 >;            /* in zephyr/dts/vendor/nordic/nrf54l_05_10_15.dtsi:746 */
			override-granularity = < 0x1000 >; /* in zephyr/dts/vendor/nordic/nrf54l_05_10_15.dtsi:747 */
		};

		/* node '/soc/cpuapp-ppb-bus' defined in zephyr/dts/vendor/nordic/nrf54l_05_10_15.dtsi:750 */
		cpuapp_ppb: cpuapp-ppb-bus {
			#address-cells = < 0x1 >;  /* in zephyr/dts/vendor/nordic/nrf54l_05_10_15.dtsi:751 */
			#size-cells = < 0x1 >;     /* in zephyr/dts/vendor/nordic/nrf54l_05_10_15.dtsi:752 */
			compatible = "simple-bus"; /* in zephyr/dts/arm/nordic/nrf54l_05_10_15_cpuapp.dtsi:67 */
			ranges;                    /* in zephyr/dts/arm/nordic/nrf54l_05_10_15_cpuapp.dtsi:68 */

			/* node '/soc/cpuapp-ppb-bus/interrupt-controller@e000e100' defined in zephyr/dts/vendor/nordic/nrf54l_05_10_15.dtsi:754 */
			cpuapp_nvic: nvic: interrupt-controller@e000e100 {
				#address-cells = < 0x1 >;            /* in zephyr/dts/vendor/nordic/nrf54l_05_10_15.dtsi:755 */
				compatible = "arm,v8m-nvic";         /* in zephyr/dts/vendor/nordic/nrf54l_05_10_15.dtsi:756 */
				reg = < 0xe000e100 0xc00 >;          /* in zephyr/dts/vendor/nordic/nrf54l_05_10_15.dtsi:757 */
				arm,num-irq-priority-bits = < 0x3 >; /* in zephyr/dts/vendor/nordic/nrf54l_05_10_15.dtsi:758 */
				interrupt-controller;                /* in zephyr/dts/vendor/nordic/nrf54l_05_10_15.dtsi:759 */
				#interrupt-cells = < 0x2 >;          /* in zephyr/dts/vendor/nordic/nrf54l_05_10_15.dtsi:760 */
				phandle = < 0x2 >;                   /* in zephyr/dts/arm/nordic/nrf54l_05_10_15_cpuapp.dtsi:26 */
			};

			/* node '/soc/cpuapp-ppb-bus/timer@e000e010' defined in zephyr/dts/vendor/nordic/nrf54l_05_10_15.dtsi:763 */
			cpuapp_systick: systick: timer@e000e010 {
				compatible = "arm,armv8m-systick"; /* in zephyr/dts/vendor/nordic/nrf54l_05_10_15.dtsi:764 */
				reg = < 0xe000e010 0x10 >;         /* in zephyr/dts/vendor/nordic/nrf54l_05_10_15.dtsi:765 */
				status = "disabled";               /* in zephyr/dts/vendor/nordic/nrf54l_05_10_15.dtsi:766 */
			};
		};
	};

	/* node '/chosen' defined in zephyr/dts/arm/nordic/nrf54l_05_10_15_cpuapp.dtsi:19 */
	chosen {
		zephyr,bt-hci = &bt_hci_sdc;              /* in zephyr/dts/arm/nordic/nrf54l_05_10_15_cpuapp.dtsi:20 */
		zephyr,entropy = &psa_rng;                /* in zephyr/dts/arm/nordic/nrf54l_05_10_15_cpuapp.dtsi:21 */
		zephyr,code-partition = &slot0_partition; /* in zephyr/boards/seeed/xiao_nrf54l15/xiao_nrf54l15_nrf54l15_cpuapp.dts:41 */
		zephyr,sram = &cpuapp_sram;               /* in zephyr/boards/seeed/xiao_nrf54l15/xiao_nrf54l15_nrf54l15_cpuapp.dts:42 */
		zephyr,flash = &cpuapp_rram;              /* in zephyr/boards/seeed/xiao_nrf54l15/xiao_nrf54l15_nrf54l15_cpuapp.dts:43 */
		zephyr,console = &uart20;                 /* in zephyr/boards/seeed/xiao_nrf54l15/xiao_nrf54l15_nrf54l15_cpuapp.dts:44 */
		zephyr,shell-uart = &uart20;              /* in zephyr/boards/seeed/xiao_nrf54l15/xiao_nrf54l15_nrf54l15_cpuapp.dts:45 */
		nordic,rpc-uart = &uart20;                /* in zephyr/boards/seeed/xiao_nrf54l15/xiao_nrf54l15_nrf54l15_cpuapp.dts:46 */
	};

	/* node '/rng' defined in zephyr/dts/arm/nordic/nrf54l_05_10_15_cpuapp.dtsi:30 */
	rng: rng {
		status = "disabled";                      /* in zephyr/dts/arm/nordic/nrf54l_05_10_15_cpuapp.dtsi:31 */
		compatible = "nordic,nrf-cracen-ctrdrbg"; /* in zephyr/dts/arm/nordic/nrf54l_05_10_15_cpuapp.dtsi:32 */
	};

	/* node '/psa-rng' defined in zephyr/dts/arm/nordic/nrf54l_05_10_15_cpuapp.dtsi:35 */
	psa_rng: psa-rng {
		compatible = "zephyr,psa-crypto-rng"; /* in zephyr/dts/arm/nordic/nrf54l_05_10_15_cpuapp.dtsi:36 */
		status = "okay";                      /* in zephyr/dts/arm/nordic/nrf54l_05_10_15_cpuapp.dtsi:37 */
	};

	/* node '/connector' defined in zephyr/boards/seeed/xiao_nrf54l15/seeed_xiao_connector.dtsi:6 */
	xiao_d: connector {
		compatible = "seeed,xiao-gpio";            /* in zephyr/boards/seeed/xiao_nrf54l15/seeed_xiao_connector.dtsi:7 */
		#gpio-cells = < 0x2 >;                     /* in zephyr/boards/seeed/xiao_nrf54l15/seeed_xiao_connector.dtsi:8 */
		gpio-map-mask = < 0xffffffff 0xffffffc0 >; /* in zephyr/boards/seeed/xiao_nrf54l15/seeed_xiao_connector.dtsi:9 */
		gpio-map-pass-thru = < 0x0 0x3f >;         /* in zephyr/boards/seeed/xiao_nrf54l15/seeed_xiao_connector.dtsi:10 */
		gpio-map = < 0x0 0x0 &gpio1 0x4 0x0 >,
		           < 0x1 0x0 &gpio1 0x5 0x0 >,
		           < 0x2 0x0 &gpio1 0x6 0x0 >,
		           < 0x3 0x0 &gpio1 0x7 0x0 >,
		           < 0x4 0x0 &gpio1 0xa 0x0 >,
		           < 0x5 0x0 &gpio1 0xb 0x0 >,
		           < 0x6 0x0 &gpio2 0x8 0x0 >,
		           < 0x7 0x0 &gpio2 0x7 0x0 >,
		           < 0x8 0x0 &gpio2 0x1 0x0 >,
		           < 0x9 0x0 &gpio2 0x4 0x0 >,
		           < 0xa 0x0 &gpio2 0x2 0x0 >;     /* in zephyr/boards/seeed/xiao_nrf54l15/seeed_xiao_connector.dtsi:11 */
	};

	/* node '/leds' defined in zephyr/boards/seeed/xiao_nrf54l15/xiao_nrf54l15_common.dtsi:9 */
	leds {
		compatible = "gpio-leds"; /* in zephyr/boards/seeed/xiao_nrf54l15/xiao_nrf54l15_common.dtsi:10 */

		/* node '/leds/led_0' defined in zephyr/boards/seeed/xiao_nrf54l15/xiao_nrf54l15_common.dtsi:12 */
		led0: led_0 {
			gpios = < &gpio2 0x0 0x0 >; /* in zephyr/boards/seeed/xiao_nrf54l15/xiao_nrf54l15_common.dtsi:13 */
			label = "LED 0";            /* in zephyr/boards/seeed/xiao_nrf54l15/xiao_nrf54l15_common.dtsi:14 */
		};
	};

	/* node '/buttons' defined in zephyr/boards/seeed/xiao_nrf54l15/xiao_nrf54l15_common.dtsi:18 */
	buttons: buttons {
		compatible = "gpio-keys"; /* in zephyr/boards/seeed/xiao_nrf54l15/xiao_nrf54l15_common.dtsi:19 */

		/* node '/buttons/usr-btn' defined in zephyr/boards/seeed/xiao_nrf54l15/xiao_nrf54l15_common.dtsi:21 */
		usr_btn: usr-btn {
			gpios = < &gpio0 0x0 0x11 >; /* in zephyr/boards/seeed/xiao_nrf54l15/xiao_nrf54l15_common.dtsi:22 */
			label = "USR";               /* in zephyr/boards/seeed/xiao_nrf54l15/xiao_nrf54l15_common.dtsi:23 */
			zephyr,code = < 0x1c >;      /* in zephyr/boards/seeed/xiao_nrf54l15/xiao_nrf54l15_common.dtsi:24 */
		};
	};

	/* node '/aliases' defined in zephyr/boards/seeed/xiao_nrf54l15/xiao_nrf54l15_common.dtsi:28 */
	aliases {
		led0 = &led0;         /* in zephyr/boards/seeed/xiao_nrf54l15/xiao_nrf54l15_common.dtsi:29 */
		buttons = &buttons;   /* in zephyr/boards/seeed/xiao_nrf54l15/xiao_nrf54l15_common.dtsi:30 */
		dmic20 = &pdm20;      /* in zephyr/boards/seeed/xiao_nrf54l15/xiao_nrf54l15_common.dtsi:31 */
		sw0 = &usr_btn;       /* in zephyr/boards/seeed/xiao_nrf54l15/xiao_nrf54l15_common.dtsi:32 */
		watchdog0 = &wdt31;   /* in zephyr/boards/seeed/xiao_nrf54l15/xiao_nrf54l15_common.dtsi:33 */
		imu0 = &lsm6dso;      /* in zephyr/boards/seeed/xiao_nrf54l15/xiao_nrf54l15_nrf54l15_cpuapp.dts:50 */
		boost-en = &boost_en; /* in ../../Documents/Projects/PlantSensor/zephyr/boards/xiao_nrf54l15_nrf54l15_cpuapp.overlay:64 */
		soil-pwr = &soil_pwr; /* in ../../Documents/Projects/PlantSensor/zephyr/boards/xiao_nrf54l15_nrf54l15_cpuapp.overlay:65 */
		user-led = &led0;     /* in ../../Documents/Projects/PlantSensor/zephyr/boards/xiao_nrf54l15_nrf54l15_cpuapp.overlay:66 */
	};

	/* node '/pdm-imu-pwr' defined in zephyr/boards/seeed/xiao_nrf54l15/xiao_nrf54l15_nrf54l15_cpuapp.dts:14 */
	pdm_imu_pwr: pdm-imu-pwr {
		compatible = "regulator-fixed";    /* in zephyr/boards/seeed/xiao_nrf54l15/xiao_nrf54l15_nrf54l15_cpuapp.dts:15 */
		regulator-name = "pdm-imu-pwr";    /* in zephyr/boards/seeed/xiao_nrf54l15/xiao_nrf54l15_nrf54l15_cpuapp.dts:16 */
		enable-gpios = < &gpio0 0x1 0x0 >; /* in zephyr/boards/seeed/xiao_nrf54l15/xiao_nrf54l15_nrf54l15_cpuapp.dts:17 */
		regulator-boot-on;                 /* in zephyr/boards/seeed/xiao_nrf54l15/xiao_nrf54l15_nrf54l15_cpuapp.dts:18 */
		startup-delay-us = < 0x1388 >;     /* in zephyr/boards/seeed/xiao_nrf54l15/xiao_nrf54l15_nrf54l15_cpuapp.dts:19 */
	};

	/* node '/rfsw-ctl' defined in zephyr/boards/seeed/xiao_nrf54l15/xiao_nrf54l15_nrf54l15_cpuapp.dts:22 */
	rfsw_ctl: rfsw-ctl {
		compatible = "regulator-fixed";    /* in zephyr/boards/seeed/xiao_nrf54l15/xiao_nrf54l15_nrf54l15_cpuapp.dts:23 */
		regulator-name = "rfsw-ctl";       /* in zephyr/boards/seeed/xiao_nrf54l15/xiao_nrf54l15_nrf54l15_cpuapp.dts:24 */
		enable-gpios = < &gpio2 0x5 0x0 >; /* in zephyr/boards/seeed/xiao_nrf54l15/xiao_nrf54l15_nrf54l15_cpuapp.dts:25 */
		regulator-boot-on;                 /* in ../../Documents/Projects/PlantSensor/zephyr/boards/xiao_nrf54l15_nrf54l15_cpuapp.overlay:21 */
	};

	/* node '/rfsw-pwr' defined in zephyr/boards/seeed/xiao_nrf54l15/xiao_nrf54l15_nrf54l15_cpuapp.dts:28 */
	rfsw_pwr: rfsw-pwr {
		compatible = "regulator-fixed";    /* in zephyr/boards/seeed/xiao_nrf54l15/xiao_nrf54l15_nrf54l15_cpuapp.dts:29 */
		regulator-name = "rfsw-pwr";       /* in zephyr/boards/seeed/xiao_nrf54l15/xiao_nrf54l15_nrf54l15_cpuapp.dts:30 */
		enable-gpios = < &gpio2 0x3 0x0 >; /* in zephyr/boards/seeed/xiao_nrf54l15/xiao_nrf54l15_nrf54l15_cpuapp.dts:31 */
		regulator-boot-on;                 /* in ../../Documents/Projects/PlantSensor/zephyr/boards/xiao_nrf54l15_nrf54l15_cpuapp.overlay:17 */
	};

	/* node '/vbat-pwr' defined in zephyr/boards/seeed/xiao_nrf54l15/xiao_nrf54l15_nrf54l15_cpuapp.dts:34 */
	vbat_pwr: vbat-pwr {
		compatible = "regulator-fixed";    /* in zephyr/boards/seeed/xiao_nrf54l15/xiao_nrf54l15_nrf54l15_cpuapp.dts:35 */
		regulator-name = "vbat";           /* in zephyr/boards/seeed/xiao_nrf54l15/xiao_nrf54l15_nrf54l15_cpuapp.dts:36 */
		enable-gpios = < &gpio1 0xf 0x0 >; /* in zephyr/boards/seeed/xiao_nrf54l15/xiao_nrf54l15_nrf54l15_cpuapp.dts:37 */
	};

	/* node '/zephyr,user' defined in ../../Documents/Projects/PlantSensor/zephyr/boards/xiao_nrf54l15_nrf54l15_cpuapp.overlay:42 */
	zephyr,user {
		io-channels = < &adc 0x1 >,
		              < &adc 0x2 >; /* in ../../Documents/Projects/PlantSensor/zephyr/boards/xiao_nrf54l15_nrf54l15_cpuapp.overlay:43 */
	};

	/* node '/myco_gpios' defined in ../../Documents/Projects/PlantSensor/zephyr/boards/xiao_nrf54l15_nrf54l15_cpuapp.overlay:49 */
	myco_gpios {
		compatible = "gpio-leds"; /* in ../../Documents/Projects/PlantSensor/zephyr/boards/xiao_nrf54l15_nrf54l15_cpuapp.overlay:50 */

		/* node '/myco_gpios/boost_en' defined in ../../Documents/Projects/PlantSensor/zephyr/boards/xiao_nrf54l15_nrf54l15_cpuapp.overlay:52 */
		boost_en: boost_en {
			gpios = < &gpio2 0x1 0x1 >; /* in ../../Documents/Projects/PlantSensor/zephyr/boards/xiao_nrf54l15_nrf54l15_cpuapp.overlay:53 */
			label = "Boost EN";         /* in ../../Documents/Projects/PlantSensor/zephyr/boards/xiao_nrf54l15_nrf54l15_cpuapp.overlay:54 */
		};

		/* node '/myco_gpios/soil_pwr' defined in ../../Documents/Projects/PlantSensor/zephyr/boards/xiao_nrf54l15_nrf54l15_cpuapp.overlay:57 */
		soil_pwr: soil_pwr {
			gpios = < &gpio2 0x2 0x0 >; /* in ../../Documents/Projects/PlantSensor/zephyr/boards/xiao_nrf54l15_nrf54l15_cpuapp.overlay:58 */
			label = "Soil PWR";         /* in ../../Documents/Projects/PlantSensor/zephyr/boards/xiao_nrf54l15_nrf54l15_cpuapp.overlay:59 */
		};
	};
};
